AUTOSAR XML (schema 4-0-3)
standard types defined: uint8, Boolean, UInt16, UInt8, boolean
package /AUTOSAR_Platform/DataConstrs
  range DC_Boolean: raw 0..1
  range DC_UInt16: raw 0..65535
  range DC_UInt8: raw 0..255
package /DataTypes/Units
  unit NoUnit1: display-name=NoUnit, factor-si-to-unit=1, offset-si-to-unit=0
package /PATAC/Facility/DataTypes/Implementation
  compu method COMPU_Boolean: 0=FALSE, 1=TRUE
  unit NoUnit: factor-si-to-unit=1, offset-si-to-unit=0
package /PATAC/MSM/DataTypes
  impl type SeatChldLkSt: category=VALUE, base-type=BaseTypes/uint8, compu {0=ChldLkSt_NoActive, 1=ChldLkSt_Lock, 2=ChldLkSt_Unlock}
  parameter interface SeatMovCfg
    parameter data prototype Val: sw-calibration-access=READ-WRITE, type=UInt8
package /PATAC/MSM/DataTypes/Implementation
  impl type SeatSysVoltSt: category=VALUE, base-type=UInt8, compu {0=CeSMS_SysVoltNormal, 1=CeSMS_SysVoltLow, 2=CeSMS_SysVoltHigh, 3=CeSMS_SysVoltLow1, 4=CeSMS_SysVoltLow2, 5=CeSMS_SysVoltHigh1, 6=CeSMS_SysVoltHigh2}, range raw -INF..INF, type-emitter=RTE
package /PATAC/MSM/DataTypes/ImplementationDataTypes
  impl type IfVeSMSeStNumConfig: category=VALUE, base-type=UInt8, sw-calibration-access=READ-ONLY, compu {0=SeatNum4Config, 1=SeatNum6Config, 2=SeatNum7Config, 3=SeatNum4PConfig, 4=SeatNumNDLBLow, 5=SeatNumNDLBHigh}, type-emitter=RTE
package /PATAC/MSM/ModeAdjust
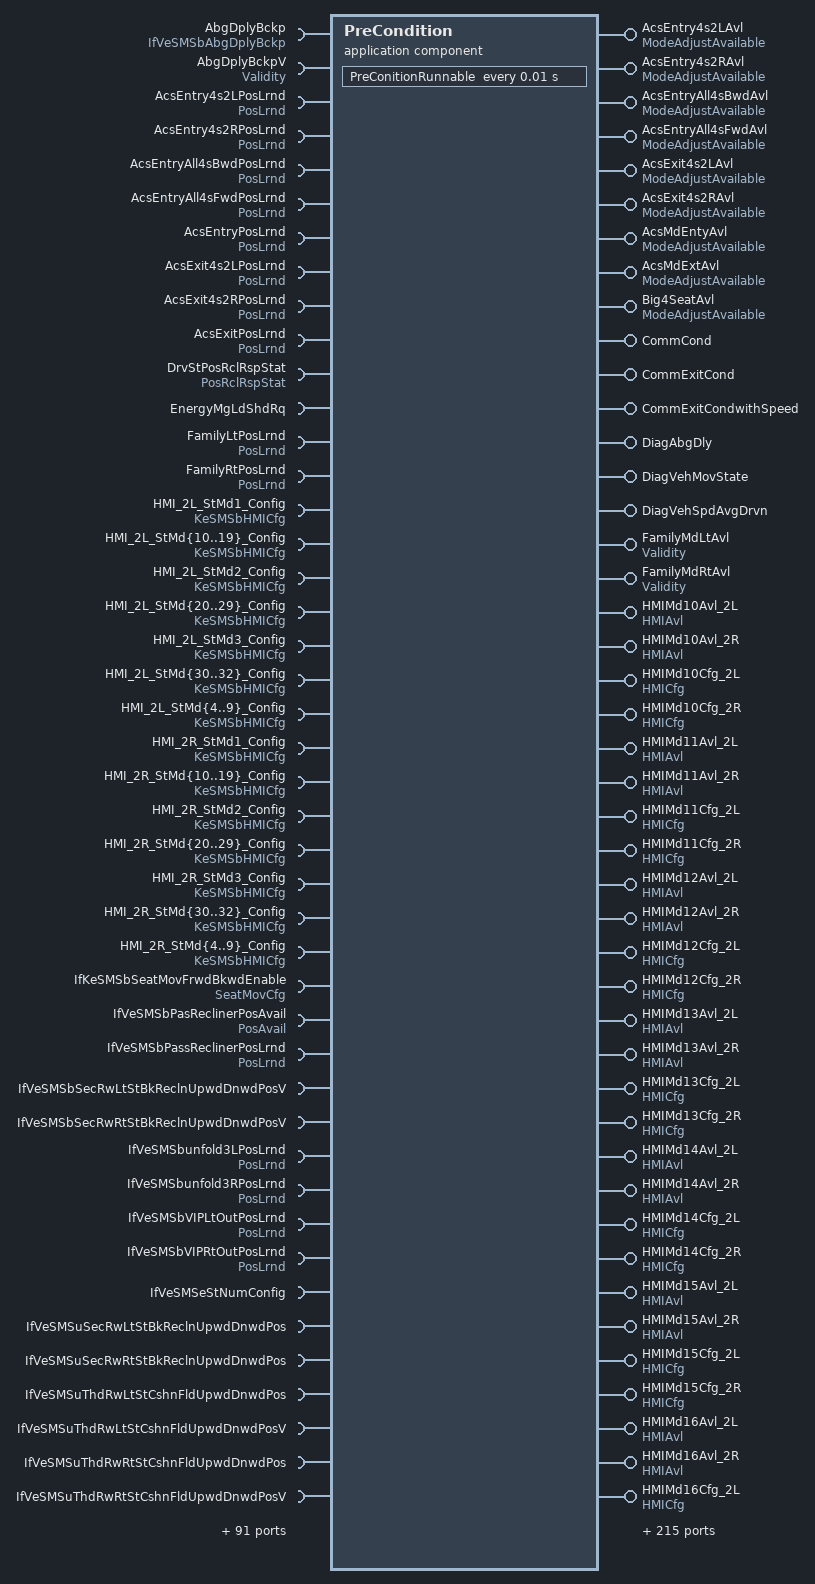
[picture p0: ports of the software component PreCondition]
  application sw component type PreCondition
    309 x provide port:
      AcsEntry4s2LAvl: nonqueued-sender-com-spec{data-element=ModeAdjustAvailable/Val, init-value=0}, provided-interface=ModeAdjustAvailable
      AcsEntry4s2RAvl: nonqueued-sender-com-spec{data-element=ModeAdjustAvailable/Val, init-value=0}, provided-interface=ModeAdjustAvailable
      AcsEntryAll4sBwdAvl: nonqueued-sender-com-spec{data-element=ModeAdjustAvailable/Val, init-value=0}, provided-interface=ModeAdjustAvailable
      AcsEntryAll4sFwdAvl: nonqueued-sender-com-spec{data-element=ModeAdjustAvailable/Val, init-value=0}, provided-interface=ModeAdjustAvailable
      AcsExit4s2LAvl: nonqueued-sender-com-spec{data-element=ModeAdjustAvailable/Val, init-value=0}, provided-interface=ModeAdjustAvailable
      AcsExit4s2RAvl: nonqueued-sender-com-spec{data-element=ModeAdjustAvailable/Val, init-value=0}, provided-interface=ModeAdjustAvailable
      AcsMdEntyAvl: nonqueued-sender-com-spec{data-element=ModeAdjustAvailable/Val, init-value=0}, provided-interface=ModeAdjustAvailable
      AcsMdExtAvl: nonqueued-sender-com-spec{data-element=ModeAdjustAvailable/Val, init-value=0}, provided-interface=ModeAdjustAvailable
      Big4SeatAvl: nonqueued-sender-com-spec{data-element=ModeAdjustAvailable/Val, init-value=0}, provided-interface=ModeAdjustAvailable
      CommCond: nonqueued-sender-com-spec=data-element=CommCond/Val, provided-interface=CommCond
      CommExitCond: nonqueued-sender-com-spec=data-element=CommExitCond/Val, provided-interface=CommExitCond
      CommExitCondwithSpeed: nonqueued-sender-com-spec=data-element=CommExitCondwithSpeed/Val, provided-interface=CommExitCondwithSpeed
      DiagAbgDly: nonqueued-sender-com-spec=data-element=DiagAbgDly/Val, provided-interface=DiagAbgDly
      DiagVehMovState: nonqueued-sender-com-spec=data-element=DiagVehMovState/Val, provided-interface=DiagVehMovState
      DiagVehSpdAvgDrvn: nonqueued-sender-com-spec=data-element=DiagVehSpdAvgDrvn/Val, provided-interface=DiagVehSpdAvgDrvn
      FamilyMdLtAvl: nonqueued-sender-com-spec{data-element=Validity/Val, init-value=0}, provided-interface=Validity
      FamilyMdRtAvl: nonqueued-sender-com-spec{data-element=Validity/Val, init-value=0}, provided-interface=Validity
      HMIMd10Avl_2L: nonqueued-sender-com-spec{data-element=HMIAvl/Val, init-value=0}, provided-interface=HMIAvl
      HMIMd10Avl_2R: nonqueued-sender-com-spec{data-element=HMIAvl/Val, init-value=0}, provided-interface=HMIAvl
      HMIMd10Cfg_2L: nonqueued-sender-com-spec{data-element=HMICfg/Val, init-value=0}, provided-interface=HMICfg
      HMIMd10Cfg_2R: nonqueued-sender-com-spec{data-element=HMICfg/Val, init-value=0}, provided-interface=HMICfg
      HMIMd11Avl_2L: nonqueued-sender-com-spec{data-element=HMIAvl/Val, init-value=0}, provided-interface=HMIAvl
      HMIMd11Avl_2R: nonqueued-sender-com-spec{data-element=HMIAvl/Val, init-value=0}, provided-interface=HMIAvl
      HMIMd11Cfg_2L: nonqueued-sender-com-spec{data-element=HMICfg/Val, init-value=0}, provided-interface=HMICfg
      HMIMd11Cfg_2R: nonqueued-sender-com-spec{data-element=HMICfg/Val, init-value=0}, provided-interface=HMICfg
      HMIMd12Avl_2L: nonqueued-sender-com-spec{data-element=HMIAvl/Val, init-value=0}, provided-interface=HMIAvl
      HMIMd12Avl_2R: nonqueued-sender-com-spec{data-element=HMIAvl/Val, init-value=0}, provided-interface=HMIAvl
      HMIMd12Cfg_2L: nonqueued-sender-com-spec{data-element=HMICfg/Val, init-value=0}, provided-interface=HMICfg
      HMIMd12Cfg_2R: nonqueued-sender-com-spec{data-element=HMICfg/Val, init-value=0}, provided-interface=HMICfg
      HMIMd13Avl_2L: nonqueued-sender-com-spec{data-element=HMIAvl/Val, init-value=0}, provided-interface=HMIAvl
      HMIMd13Avl_2R: nonqueued-sender-com-spec{data-element=HMIAvl/Val, init-value=0}, provided-interface=HMIAvl
      HMIMd13Cfg_2L: nonqueued-sender-com-spec{data-element=HMICfg/Val, init-value=0}, provided-interface=HMICfg
      HMIMd13Cfg_2R: nonqueued-sender-com-spec{data-element=HMICfg/Val, init-value=0}, provided-interface=HMICfg
      HMIMd14Avl_2L: nonqueued-sender-com-spec{data-element=HMIAvl/Val, init-value=0}, provided-interface=HMIAvl
      HMIMd14Avl_2R: nonqueued-sender-com-spec{data-element=HMIAvl/Val, init-value=0}, provided-interface=HMIAvl
      HMIMd14Cfg_2L: nonqueued-sender-com-spec{data-element=HMICfg/Val, init-value=0}, provided-interface=HMICfg
      HMIMd14Cfg_2R: nonqueued-sender-com-spec{data-element=HMICfg/Val, init-value=0}, provided-interface=HMICfg
      HMIMd15Avl_2L: nonqueued-sender-com-spec{data-element=HMIAvl/Val, init-value=0}, provided-interface=HMIAvl
      HMIMd15Avl_2R: nonqueued-sender-com-spec{data-element=HMIAvl/Val, init-value=0}, provided-interface=HMIAvl
      HMIMd15Cfg_2L: nonqueued-sender-com-spec{data-element=HMICfg/Val, init-value=0}, provided-interface=HMICfg
      HMIMd15Cfg_2R: nonqueued-sender-com-spec{data-element=HMICfg/Val, init-value=0}, provided-interface=HMICfg
      HMIMd16Avl_2L: nonqueued-sender-com-spec{data-element=HMIAvl/Val, init-value=0}, provided-interface=HMIAvl
      HMIMd16Avl_2R: nonqueued-sender-com-spec{data-element=HMIAvl/Val, init-value=0}, provided-interface=HMIAvl
      HMIMd16Cfg_2L: nonqueued-sender-com-spec{data-element=HMICfg/Val, init-value=0}, provided-interface=HMICfg
      HMIMd16Cfg_2R: nonqueued-sender-com-spec{data-element=HMICfg/Val, init-value=0}, provided-interface=HMICfg
      HMIMd17Avl_2L: nonqueued-sender-com-spec{data-element=HMIAvl/Val, init-value=0}, provided-interface=HMIAvl
      HMIMd17Avl_2R: nonqueued-sender-com-spec{data-element=HMIAvl/Val, init-value=0}, provided-interface=HMIAvl
      HMIMd17Cfg_2L: nonqueued-sender-com-spec{data-element=HMICfg/Val, init-value=0}, provided-interface=HMICfg
      HMIMd17Cfg_2R: nonqueued-sender-com-spec{data-element=HMICfg/Val, init-value=0}, provided-interface=HMICfg
      HMIMd18Avl_2L: nonqueued-sender-com-spec{data-element=HMIAvl/Val, init-value=0}, provided-interface=HMIAvl
      HMIMd18Avl_2R: nonqueued-sender-com-spec{data-element=HMIAvl/Val, init-value=0}, provided-interface=HMIAvl
      HMIMd18Cfg_2L: nonqueued-sender-com-spec{data-element=HMICfg/Val, init-value=0}, provided-interface=HMICfg
      HMIMd18Cfg_2R: nonqueued-sender-com-spec{data-element=HMICfg/Val, init-value=0}, provided-interface=HMICfg
      HMIMd19Avl_2L: nonqueued-sender-com-spec{data-element=HMIAvl/Val, init-value=0}, provided-interface=HMIAvl
      HMIMd19Avl_2R: nonqueued-sender-com-spec{data-element=HMIAvl/Val, init-value=0}, provided-interface=HMIAvl
      HMIMd19Cfg_2L: nonqueued-sender-com-spec{data-element=HMICfg/Val, init-value=0}, provided-interface=HMICfg
      HMIMd19Cfg_2R: nonqueued-sender-com-spec{data-element=HMICfg/Val, init-value=0}, provided-interface=HMICfg
      HMIMd1Avl_2L: nonqueued-sender-com-spec{data-element=HMIAvl/Val, init-value=0}, provided-interface=HMIAvl
      HMIMd1Avl_2R: nonqueued-sender-com-spec{data-element=HMIAvl/Val, init-value=0}, provided-interface=HMIAvl
      HMIMd1Cfg_2L: nonqueued-sender-com-spec{data-element=HMICfg/Val, init-value=0}, provided-interface=HMICfg
      HMIMd1Cfg_2R: nonqueued-sender-com-spec{data-element=HMICfg/Val, init-value=0}, provided-interface=HMICfg
      HMIMd20Avl_2L: nonqueued-sender-com-spec{data-element=HMIAvl/Val, init-value=0}, provided-interface=HMIAvl
      HMIMd20Avl_2R: nonqueued-sender-com-spec{data-element=HMIAvl/Val, init-value=0}, provided-interface=HMIAvl
      HMIMd20Cfg_2L: nonqueued-sender-com-spec{data-element=HMICfg/Val, init-value=0}, provided-interface=HMICfg
      HMIMd20Cfg_2R: nonqueued-sender-com-spec{data-element=HMICfg/Val, init-value=0}, provided-interface=HMICfg
      HMIMd21Avl_2L: nonqueued-sender-com-spec{data-element=HMIAvl/Val, init-value=0}, provided-interface=HMIAvl
      HMIMd21Avl_2R: nonqueued-sender-com-spec{data-element=HMIAvl/Val, init-value=0}, provided-interface=HMIAvl
      HMIMd21Cfg_2L: nonqueued-sender-com-spec{data-element=HMICfg/Val, init-value=0}, provided-interface=HMICfg
      HMIMd21Cfg_2R: nonqueued-sender-com-spec{data-element=HMICfg/Val, init-value=0}, provided-interface=HMICfg
      HMIMd22Avl_2L: nonqueued-sender-com-spec{data-element=HMIAvl/Val, init-value=0}, provided-interface=HMIAvl
      HMIMd22Avl_2R: nonqueued-sender-com-spec{data-element=HMIAvl/Val, init-value=0}, provided-interface=HMIAvl
      HMIMd22Cfg_2L: nonqueued-sender-com-spec{data-element=HMICfg/Val, init-value=0}, provided-interface=HMICfg
      HMIMd22Cfg_2R: nonqueued-sender-com-spec{data-element=HMICfg/Val, init-value=0}, provided-interface=HMICfg
      HMIMd23Avl_2L: nonqueued-sender-com-spec{data-element=HMIAvl/Val, init-value=0}, provided-interface=HMIAvl
      HMIMd23Avl_2R: nonqueued-sender-com-spec{data-element=HMIAvl/Val, init-value=0}, provided-interface=HMIAvl
      HMIMd23Cfg_2L: nonqueued-sender-com-spec{data-element=HMICfg/Val, init-value=0}, provided-interface=HMICfg
      HMIMd23Cfg_2R: nonqueued-sender-com-spec{data-element=HMICfg/Val, init-value=0}, provided-interface=HMICfg
      HMIMd24Avl_2L: nonqueued-sender-com-spec{data-element=HMIAvl/Val, init-value=0}, provided-interface=HMIAvl
      HMIMd24Avl_2R: nonqueued-sender-com-spec{data-element=HMIAvl/Val, init-value=0}, provided-interface=HMIAvl
      HMIMd24Cfg_2L: nonqueued-sender-com-spec{data-element=HMICfg/Val, init-value=0}, provided-interface=HMICfg
      HMIMd24Cfg_2R: nonqueued-sender-com-spec{data-element=HMICfg/Val, init-value=0}, provided-interface=HMICfg
      HMIMd25Avl_2L: nonqueued-sender-com-spec{data-element=HMIAvl/Val, init-value=0}, provided-interface=HMIAvl
      HMIMd25Avl_2R: nonqueued-sender-com-spec{data-element=HMIAvl/Val, init-value=0}, provided-interface=HMIAvl
      HMIMd25Cfg_2L: nonqueued-sender-com-spec{data-element=HMICfg/Val, init-value=0}, provided-interface=HMICfg
      HMIMd25Cfg_2R: nonqueued-sender-com-spec{data-element=HMICfg/Val, init-value=0}, provided-interface=HMICfg
      HMIMd26Avl_2L: nonqueued-sender-com-spec{data-element=HMIAvl/Val, init-value=0}, provided-interface=HMIAvl
      HMIMd26Avl_2R: nonqueued-sender-com-spec{data-element=HMIAvl/Val, init-value=0}, provided-interface=HMIAvl
      HMIMd26Cfg_2L: nonqueued-sender-com-spec{data-element=HMICfg/Val, init-value=0}, provided-interface=HMICfg
      HMIMd26Cfg_2R: nonqueued-sender-com-spec{data-element=HMICfg/Val, init-value=0}, provided-interface=HMICfg
      HMIMd27Avl_2L: nonqueued-sender-com-spec{data-element=HMIAvl/Val, init-value=0}, provided-interface=HMIAvl
      HMIMd27Avl_2R: nonqueued-sender-com-spec{data-element=HMIAvl/Val, init-value=0}, provided-interface=HMIAvl
      HMIMd27Cfg_2L: nonqueued-sender-com-spec{data-element=HMICfg/Val, init-value=0}, provided-interface=HMICfg
      HMIMd27Cfg_2R: nonqueued-sender-com-spec{data-element=HMICfg/Val, init-value=0}, provided-interface=HMICfg
      HMIMd28Avl_2L: nonqueued-sender-com-spec{data-element=HMIAvl/Val, init-value=0}, provided-interface=HMIAvl
      HMIMd28Avl_2R: nonqueued-sender-com-spec{data-element=HMIAvl/Val, init-value=0}, provided-interface=HMIAvl
      HMIMd28Cfg_2L: nonqueued-sender-com-spec{data-element=HMICfg/Val, init-value=0}, provided-interface=HMICfg
      HMIMd28Cfg_2R: nonqueued-sender-com-spec{data-element=HMICfg/Val, init-value=0}, provided-interface=HMICfg
      HMIMd29Avl_2L: nonqueued-sender-com-spec{data-element=HMIAvl/Val, init-value=0}, provided-interface=HMIAvl
      HMIMd29Avl_2R: nonqueued-sender-com-spec{data-element=HMIAvl/Val, init-value=0}, provided-interface=HMIAvl
      HMIMd29Cfg_2L: nonqueued-sender-com-spec{data-element=HMICfg/Val, init-value=0}, provided-interface=HMICfg
      HMIMd29Cfg_2R: nonqueued-sender-com-spec{data-element=HMICfg/Val, init-value=0}, provided-interface=HMICfg
      HMIMd2Avl_2L: nonqueued-sender-com-spec{data-element=HMIAvl/Val, init-value=0}, provided-interface=HMIAvl
      HMIMd2Avl_2R: nonqueued-sender-com-spec{data-element=HMIAvl/Val, init-value=0}, provided-interface=HMIAvl
      HMIMd2Cfg_2L: nonqueued-sender-com-spec{data-element=HMICfg/Val, init-value=0}, provided-interface=HMICfg
      HMIMd2Cfg_2R: nonqueued-sender-com-spec{data-element=HMICfg/Val, init-value=0}, provided-interface=HMICfg
      HMIMd30Avl_2L: nonqueued-sender-com-spec{data-element=HMIAvl/Val, init-value=0}, provided-interface=HMIAvl
      HMIMd30Avl_2R: nonqueued-sender-com-spec{data-element=HMIAvl/Val, init-value=0}, provided-interface=HMIAvl
      HMIMd30Cfg_2L: nonqueued-sender-com-spec{data-element=HMICfg/Val, init-value=0}, provided-interface=HMICfg
      HMIMd30Cfg_2R: nonqueued-sender-com-spec{data-element=HMICfg/Val, init-value=0}, provided-interface=HMICfg
      HMIMd31Avl_2L: nonqueued-sender-com-spec{data-element=HMIAvl/Val, init-value=0}, provided-interface=HMIAvl
      HMIMd31Avl_2R: nonqueued-sender-com-spec{data-element=HMIAvl/Val, init-value=0}, provided-interface=HMIAvl
      HMIMd31Cfg_2L: nonqueued-sender-com-spec{data-element=HMICfg/Val, init-value=0}, provided-interface=HMICfg
      HMIMd31Cfg_2R: nonqueued-sender-com-spec{data-element=HMICfg/Val, init-value=0}, provided-interface=HMICfg
      HMIMd32Avl_2L: nonqueued-sender-com-spec{data-element=HMIAvl/Val, init-value=0}, provided-interface=HMIAvl
      HMIMd32Avl_2R: nonqueued-sender-com-spec{data-element=HMIAvl/Val, init-value=0}, provided-interface=HMIAvl
      HMIMd32Cfg_2L: nonqueued-sender-com-spec{data-element=HMICfg/Val, init-value=0}, provided-interface=HMICfg
      HMIMd32Cfg_2R: nonqueued-sender-com-spec{data-element=HMICfg/Val, init-value=0}, provided-interface=HMICfg
      HMIMd3Avl_2L: nonqueued-sender-com-spec{data-element=HMIAvl/Val, init-value=0}, provided-interface=HMIAvl
      HMIMd3Avl_2R: nonqueued-sender-com-spec{data-element=HMIAvl/Val, init-value=0}, provided-interface=HMIAvl
      HMIMd3Cfg_2L: nonqueued-sender-com-spec{data-element=HMICfg/Val, init-value=0}, provided-interface=HMICfg
      HMIMd3Cfg_2R: nonqueued-sender-com-spec{data-element=HMICfg/Val, init-value=0}, provided-interface=HMICfg
      HMIMd4Avl_2L: nonqueued-sender-com-spec{data-element=HMIAvl/Val, init-value=0}, provided-interface=HMIAvl
      HMIMd4Avl_2R: nonqueued-sender-com-spec{data-element=HMIAvl/Val, init-value=0}, provided-interface=HMIAvl
      HMIMd4Cfg_2L: nonqueued-sender-com-spec{data-element=HMICfg/Val, init-value=0}, provided-interface=HMICfg
      HMIMd4Cfg_2R: nonqueued-sender-com-spec{data-element=HMICfg/Val, init-value=0}, provided-interface=HMICfg
      HMIMd5Avl_2L: nonqueued-sender-com-spec{data-element=HMIAvl/Val, init-value=0}, provided-interface=HMIAvl
      HMIMd5Avl_2R: nonqueued-sender-com-spec{data-element=HMIAvl/Val, init-value=0}, provided-interface=HMIAvl
      HMIMd5Cfg_2L: nonqueued-sender-com-spec{data-element=HMICfg/Val, init-value=0}, provided-interface=HMICfg
      HMIMd5Cfg_2R: nonqueued-sender-com-spec{data-element=HMICfg/Val, init-value=0}, provided-interface=HMICfg
      HMIMd6Avl_2L: nonqueued-sender-com-spec{data-element=HMIAvl/Val, init-value=0}, provided-interface=HMIAvl
      HMIMd6Avl_2R: nonqueued-sender-com-spec{data-element=HMIAvl/Val, init-value=0}, provided-interface=HMIAvl
      HMIMd6Cfg_2L: nonqueued-sender-com-spec{data-element=HMICfg/Val, init-value=0}, provided-interface=HMICfg
      HMIMd6Cfg_2R: nonqueued-sender-com-spec{data-element=HMICfg/Val, init-value=0}, provided-interface=HMICfg
      HMIMd7Avl_2L: nonqueued-sender-com-spec{data-element=HMIAvl/Val, init-value=0}, provided-interface=HMIAvl
      HMIMd7Avl_2R: nonqueued-sender-com-spec{data-element=HMIAvl/Val, init-value=0}, provided-interface=HMIAvl
      HMIMd7Cfg_2L: nonqueued-sender-com-spec{data-element=HMICfg/Val, init-value=0}, provided-interface=HMICfg
      HMIMd7Cfg_2R: nonqueued-sender-com-spec{data-element=HMICfg/Val, init-value=0}, provided-interface=HMICfg
      HMIMd8Avl_2L: nonqueued-sender-com-spec{data-element=HMIAvl/Val, init-value=0}, provided-interface=HMIAvl
      HMIMd8Avl_2R: nonqueued-sender-com-spec{data-element=HMIAvl/Val, init-value=0}, provided-interface=HMIAvl
      HMIMd8Cfg_2L: nonqueued-sender-com-spec{data-element=HMICfg/Val, init-value=0}, provided-interface=HMICfg
      HMIMd8Cfg_2R: nonqueued-sender-com-spec{data-element=HMICfg/Val, init-value=0}, provided-interface=HMICfg
      HMIMd9Avl_2L: nonqueued-sender-com-spec{data-element=HMIAvl/Val, init-value=0}, provided-interface=HMIAvl
      HMIMd9Avl_2R: nonqueued-sender-com-spec{data-element=HMIAvl/Val, init-value=0}, provided-interface=HMIAvl
      HMIMd9Cfg_2L: nonqueued-sender-com-spec{data-element=HMICfg/Val, init-value=0}, provided-interface=HMICfg
      HMIMd9Cfg_2R: nonqueued-sender-com-spec{data-element=HMICfg/Val, init-value=0}, provided-interface=HMICfg
      IntimacyLMdAvl: nonqueued-sender-com-spec{data-element=Validity/Val, init-value=0}, provided-interface=Validity
      IntimacyRMdAvl: nonqueued-sender-com-spec{data-element=ModeAdjustAvailable/Val, init-value=0}, provided-interface=ModeAdjustAvailable
      LgrstCloseLtMdAvl: nonqueued-sender-com-spec{data-element=ModeAdjustAvailable/Val, init-value=0}, provided-interface=ModeAdjustAvailable
      LgrstCloseRtMdAvl: nonqueued-sender-com-spec{data-element=ModeAdjustAvailable/Val, init-value=0}, provided-interface=ModeAdjustAvailable
      LgrstOpenLtMdAvl: nonqueued-sender-com-spec{data-element=ModeAdjustAvailable/Val, init-value=0}, provided-interface=ModeAdjustAvailable
      LgrstOpenRtMdAvl: nonqueued-sender-com-spec{data-element=ModeAdjustAvailable/Val, init-value=0}, provided-interface=ModeAdjustAvailable
      LugMdLtAvl: nonqueued-sender-com-spec{data-element=ModeAdjustAvailable/Val, init-value=0}, provided-interface=ModeAdjustAvailable
      LugMdRtAvl: nonqueued-sender-com-spec{data-element=ModeAdjustAvailable/Val, init-value=0}, provided-interface=ModeAdjustAvailable
      LyingMdLtAvl: nonqueued-sender-com-spec{data-element=Validity/Val, init-value=0}, provided-interface=Validity
      LyingMdRtAvl: nonqueued-sender-com-spec{data-element=Validity/Val, init-value=0}, provided-interface=Validity
      M61WholeVehMemAvl: nonqueued-sender-com-spec{data-element=ModeAdjustAvailable/Val, init-value=0}, provided-interface=ModeAdjustAvailable
      M62WholeVehMemAvl: nonqueued-sender-com-spec{data-element=ModeAdjustAvailable/Val, init-value=0}, provided-interface=ModeAdjustAvailable
      PasReclinerAvl: nonqueued-sender-com-spec{data-element=ModeAdjustAvailable/Val, init-value=0}, provided-interface=ModeAdjustAvailable
      PasReclinerExitAvl: nonqueued-sender-com-spec{data-element=ModeAdjustAvailable/Val, init-value=0}, provided-interface=ModeAdjustAvailable
      PwrMdChked: nonqueued-sender-com-spec{data-element=PowerMode/Val, init-value=0}, provided-interface=PowerMode
      RcvyMdLtAvl: nonqueued-sender-com-spec{data-element=ModeAdjustAvailable/Val, init-value=0}, provided-interface=ModeAdjustAvailable
      RcvyMdRtAvl: nonqueued-sender-com-spec{data-element=ModeAdjustAvailable/Val, init-value=0}, provided-interface=ModeAdjustAvailable
      StPassCmprtMdCtrl_Md1_VCUAvl: nonqueued-sender-com-spec{data-element=StPassCmprtMdCtrl_VCUAvl/Val, init-value=0}, provided-interface=StPassCmprtMdCtrl_VCUAvl
      StPassCmprtMdCtrl_Md1_VCUCfg: nonqueued-sender-com-spec{data-element=StPassCmprtMd_VCUCfg/Val, init-value=0}, provided-interface=StPassCmprtMd_VCUCfg
      StPassCmprtMdCtrl_Md10_VCUAvl: nonqueued-sender-com-spec{data-element=StPassCmprtMdCtrl_VCUAvl/Val, init-value=0}, provided-interface=StPassCmprtMdCtrl_VCUAvl
      StPassCmprtMdCtrl_Md10_VCUCfg: nonqueued-sender-com-spec{data-element=StPassCmprtMd_VCUCfg/Val, init-value=0}, provided-interface=StPassCmprtMd_VCUCfg
      StPassCmprtMdCtrl_Md11_VCUAvl: nonqueued-sender-com-spec{data-element=StPassCmprtMdCtrl_VCUAvl/Val, init-value=0}, provided-interface=StPassCmprtMdCtrl_VCUAvl
      StPassCmprtMdCtrl_Md11_VCUCfg: nonqueued-sender-com-spec{data-element=StPassCmprtMd_VCUCfg/Val, init-value=0}, provided-interface=StPassCmprtMd_VCUCfg
      StPassCmprtMdCtrl_Md12_VCUAvl: nonqueued-sender-com-spec{data-element=StPassCmprtMdCtrl_VCUAvl/Val, init-value=0}, provided-interface=StPassCmprtMdCtrl_VCUAvl
      StPassCmprtMdCtrl_Md12_VCUCfg: nonqueued-sender-com-spec{data-element=StPassCmprtMd_VCUCfg/Val, init-value=0}, provided-interface=StPassCmprtMd_VCUCfg
      StPassCmprtMdCtrl_Md13_VCUAvl: nonqueued-sender-com-spec{data-element=StPassCmprtMdCtrl_VCUAvl/Val, init-value=0}, provided-interface=StPassCmprtMdCtrl_VCUAvl
      StPassCmprtMdCtrl_Md13_VCUCfg: nonqueued-sender-com-spec{data-element=StPassCmprtMd_VCUCfg/Val, init-value=0}, provided-interface=StPassCmprtMd_VCUCfg
      StPassCmprtMdCtrl_Md14_VCUAvl: nonqueued-sender-com-spec{data-element=StPassCmprtMdCtrl_VCUAvl/Val, init-value=0}, provided-interface=StPassCmprtMdCtrl_VCUAvl
      StPassCmprtMdCtrl_Md14_VCUCfg: nonqueued-sender-com-spec{data-element=StPassCmprtMd_VCUCfg/Val, init-value=0}, provided-interface=StPassCmprtMd_VCUCfg
      StPassCmprtMdCtrl_Md15_VCUAvl: nonqueued-sender-com-spec{data-element=StPassCmprtMdCtrl_VCUAvl/Val, init-value=0}, provided-interface=StPassCmprtMdCtrl_VCUAvl
      StPassCmprtMdCtrl_Md15_VCUCfg: nonqueued-sender-com-spec{data-element=StPassCmprtMd_VCUCfg/Val, init-value=0}, provided-interface=StPassCmprtMd_VCUCfg
      StPassCmprtMdCtrl_Md16_VCUAvl: nonqueued-sender-com-spec{data-element=StPassCmprtMdCtrl_VCUAvl/Val, init-value=0}, provided-interface=StPassCmprtMdCtrl_VCUAvl
      StPassCmprtMdCtrl_Md16_VCUCfg: nonqueued-sender-com-spec{data-element=StPassCmprtMd_VCUCfg/Val, init-value=0}, provided-interface=StPassCmprtMd_VCUCfg
      StPassCmprtMdCtrl_Md17_VCUAvl: nonqueued-sender-com-spec{data-element=StPassCmprtMdCtrl_VCUAvl/Val, init-value=0}, provided-interface=StPassCmprtMdCtrl_VCUAvl
      StPassCmprtMdCtrl_Md17_VCUCfg: nonqueued-sender-com-spec{data-element=StPassCmprtMd_VCUCfg/Val, init-value=0}, provided-interface=StPassCmprtMd_VCUCfg
      StPassCmprtMdCtrl_Md18_VCUAvl: nonqueued-sender-com-spec{data-element=StPassCmprtMdCtrl_VCUAvl/Val, init-value=0}, provided-interface=StPassCmprtMdCtrl_VCUAvl
      StPassCmprtMdCtrl_Md18_VCUCfg: nonqueued-sender-com-spec{data-element=StPassCmprtMd_VCUCfg/Val, init-value=0}, provided-interface=StPassCmprtMd_VCUCfg
      StPassCmprtMdCtrl_Md19_VCUAvl: nonqueued-sender-com-spec{data-element=StPassCmprtMdCtrl_VCUAvl/Val, init-value=0}, provided-interface=StPassCmprtMdCtrl_VCUAvl
      StPassCmprtMdCtrl_Md19_VCUCfg: nonqueued-sender-com-spec{data-element=StPassCmprtMd_VCUCfg/Val, init-value=0}, provided-interface=StPassCmprtMd_VCUCfg
      StPassCmprtMdCtrl_Md2_VCUAvl: nonqueued-sender-com-spec{data-element=StPassCmprtMdCtrl_VCUAvl/Val, init-value=0}, provided-interface=StPassCmprtMdCtrl_VCUAvl
      StPassCmprtMdCtrl_Md2_VCUCfg: nonqueued-sender-com-spec{data-element=StPassCmprtMd_VCUCfg/Val, init-value=0}, provided-interface=StPassCmprtMd_VCUCfg
      StPassCmprtMdCtrl_Md20_VCUAvl: nonqueued-sender-com-spec{data-element=StPassCmprtMdCtrl_VCUAvl/Val, init-value=0}, provided-interface=StPassCmprtMdCtrl_VCUAvl
      StPassCmprtMdCtrl_Md20_VCUCfg: nonqueued-sender-com-spec{data-element=StPassCmprtMd_VCUCfg/Val, init-value=0}, provided-interface=StPassCmprtMd_VCUCfg
      StPassCmprtMdCtrl_Md21_VCUAvl: nonqueued-sender-com-spec{data-element=StPassCmprtMdCtrl_VCUAvl/Val, init-value=0}, provided-interface=StPassCmprtMdCtrl_VCUAvl
      StPassCmprtMdCtrl_Md21_VCUCfg: nonqueued-sender-com-spec{data-element=StPassCmprtMd_VCUCfg/Val, init-value=0}, provided-interface=StPassCmprtMd_VCUCfg
      StPassCmprtMdCtrl_Md22_VCUAvl: nonqueued-sender-com-spec{data-element=StPassCmprtMdCtrl_VCUAvl/Val, init-value=0}, provided-interface=StPassCmprtMdCtrl_VCUAvl
      StPassCmprtMdCtrl_Md22_VCUCfg: nonqueued-sender-com-spec{data-element=StPassCmprtMd_VCUCfg/Val, init-value=0}, provided-interface=StPassCmprtMd_VCUCfg
      StPassCmprtMdCtrl_Md23_VCUAvl: nonqueued-sender-com-spec{data-element=StPassCmprtMdCtrl_VCUAvl/Val, init-value=0}, provided-interface=StPassCmprtMdCtrl_VCUAvl
      StPassCmprtMdCtrl_Md23_VCUCfg: nonqueued-sender-com-spec{data-element=StPassCmprtMd_VCUCfg/Val, init-value=0}, provided-interface=StPassCmprtMd_VCUCfg
      StPassCmprtMdCtrl_Md24_VCUAvl: nonqueued-sender-com-spec{data-element=StPassCmprtMdCtrl_VCUAvl/Val, init-value=0}, provided-interface=StPassCmprtMdCtrl_VCUAvl
      StPassCmprtMdCtrl_Md24_VCUCfg: nonqueued-sender-com-spec{data-element=StPassCmprtMd_VCUCfg/Val, init-value=0}, provided-interface=StPassCmprtMd_VCUCfg
      StPassCmprtMdCtrl_Md25_VCUAvl: nonqueued-sender-com-spec{data-element=StPassCmprtMdCtrl_VCUAvl/Val, init-value=0}, provided-interface=StPassCmprtMdCtrl_VCUAvl
      StPassCmprtMdCtrl_Md25_VCUCfg: nonqueued-sender-com-spec{data-element=StPassCmprtMd_VCUCfg/Val, init-value=0}, provided-interface=StPassCmprtMd_VCUCfg
      StPassCmprtMdCtrl_Md26_VCUAvl: nonqueued-sender-com-spec{data-element=StPassCmprtMdCtrl_VCUAvl/Val, init-value=0}, provided-interface=StPassCmprtMdCtrl_VCUAvl
      StPassCmprtMdCtrl_Md26_VCUCfg: nonqueued-sender-com-spec{data-element=StPassCmprtMd_VCUCfg/Val, init-value=0}, provided-interface=StPassCmprtMd_VCUCfg
      StPassCmprtMdCtrl_Md27_VCUAvl: nonqueued-sender-com-spec{data-element=StPassCmprtMdCtrl_VCUAvl/Val, init-value=0}, provided-interface=StPassCmprtMdCtrl_VCUAvl
      StPassCmprtMdCtrl_Md27_VCUCfg: nonqueued-sender-com-spec{data-element=StPassCmprtMd_VCUCfg/Val, init-value=0}, provided-interface=StPassCmprtMd_VCUCfg
      StPassCmprtMdCtrl_Md28_VCUAvl: nonqueued-sender-com-spec{data-element=StPassCmprtMdCtrl_VCUAvl/Val, init-value=0}, provided-interface=StPassCmprtMdCtrl_VCUAvl
      StPassCmprtMdCtrl_Md28_VCUCfg: nonqueued-sender-com-spec{data-element=StPassCmprtMd_VCUCfg/Val, init-value=0}, provided-interface=StPassCmprtMd_VCUCfg
      StPassCmprtMdCtrl_Md29_VCUAvl: nonqueued-sender-com-spec{data-element=StPassCmprtMdCtrl_VCUAvl/Val, init-value=0}, provided-interface=StPassCmprtMdCtrl_VCUAvl
      StPassCmprtMdCtrl_Md29_VCUCfg: nonqueued-sender-com-spec{data-element=StPassCmprtMd_VCUCfg/Val, init-value=0}, provided-interface=StPassCmprtMd_VCUCfg
      StPassCmprtMdCtrl_Md3_VCUAvl: nonqueued-sender-com-spec{data-element=StPassCmprtMdCtrl_VCUAvl/Val, init-value=0}, provided-interface=StPassCmprtMdCtrl_VCUAvl
      StPassCmprtMdCtrl_Md3_VCUCfg: nonqueued-sender-com-spec{data-element=StPassCmprtMd_VCUCfg/Val, init-value=0}, provided-interface=StPassCmprtMd_VCUCfg
      StPassCmprtMdCtrl_Md30_VCUAvl: nonqueued-sender-com-spec{data-element=StPassCmprtMdCtrl_VCUAvl/Val, init-value=0}, provided-interface=StPassCmprtMdCtrl_VCUAvl
      StPassCmprtMdCtrl_Md30_VCUCfg: nonqueued-sender-com-spec{data-element=StPassCmprtMd_VCUCfg/Val, init-value=0}, provided-interface=StPassCmprtMd_VCUCfg
      StPassCmprtMdCtrl_Md31_VCUAvl: nonqueued-sender-com-spec{data-element=StPassCmprtMdCtrl_VCUAvl/Val, init-value=0}, provided-interface=StPassCmprtMdCtrl_VCUAvl
      StPassCmprtMdCtrl_Md31_VCUCfg: nonqueued-sender-com-spec{data-element=StPassCmprtMd_VCUCfg/Val, init-value=0}, provided-interface=StPassCmprtMd_VCUCfg
      StPassCmprtMdCtrl_Md32_VCUAvl: nonqueued-sender-com-spec{data-element=StPassCmprtMdCtrl_VCUAvl/Val, init-value=0}, provided-interface=StPassCmprtMdCtrl_VCUAvl
      StPassCmprtMdCtrl_Md32_VCUCfg: nonqueued-sender-com-spec{data-element=StPassCmprtMd_VCUCfg/Val, init-value=0}, provided-interface=StPassCmprtMd_VCUCfg
      StPassCmprtMdCtrl_Md4_VCUAvl: nonqueued-sender-com-spec{data-element=StPassCmprtMdCtrl_VCUAvl/Val, init-value=0}, provided-interface=StPassCmprtMdCtrl_VCUAvl
      StPassCmprtMdCtrl_Md4_VCUCfg: nonqueued-sender-com-spec{data-element=StPassCmprtMd_VCUCfg/Val, init-value=0}, provided-interface=StPassCmprtMd_VCUCfg
      StPassCmprtMdCtrl_Md5_VCUAvl: nonqueued-sender-com-spec{data-element=StPassCmprtMdCtrl_VCUAvl/Val, init-value=0}, provided-interface=StPassCmprtMdCtrl_VCUAvl
      StPassCmprtMdCtrl_Md5_VCUCfg: nonqueued-sender-com-spec{data-element=StPassCmprtMd_VCUCfg/Val, init-value=0}, provided-interface=StPassCmprtMd_VCUCfg
      StPassCmprtMdCtrl_Md53_VCUAvl: nonqueued-sender-com-spec{data-element=StPassCmprtMdCtrl_VCUAvl/Val, init-value=0}, provided-interface=StPassCmprtMdCtrl_VCUAvl
      StPassCmprtMdCtrl_Md53_VCUCfg: nonqueued-sender-com-spec{data-element=StPassCmprtMd_VCUCfg/Val, init-value=0}, provided-interface=StPassCmprtMd_VCUCfg
      StPassCmprtMdCtrl_Md56_VCUAvl: nonqueued-sender-com-spec{data-element=StPassCmprtMdCtrl_VCUAvl/Val, init-value=0}, provided-interface=StPassCmprtMdCtrl_VCUAvl
      StPassCmprtMdCtrl_Md56_VCUCfg: nonqueued-sender-com-spec{data-element=StPassCmprtMd_VCUCfg/Val, init-value=0}, provided-interface=StPassCmprtMd_VCUCfg
      StPassCmprtMdCtrl_Md57_VCUAvl: nonqueued-sender-com-spec{data-element=StPassCmprtMdCtrl_VCUAvl/Val, init-value=0}, provided-interface=StPassCmprtMdCtrl_VCUAvl
      StPassCmprtMdCtrl_Md57_VCUCfg: nonqueued-sender-com-spec{data-element=StPassCmprtMd_VCUCfg/Val, init-value=0}, provided-interface=StPassCmprtMd_VCUCfg
      StPassCmprtMdCtrl_Md58_VCUAvl: nonqueued-sender-com-spec{data-element=StPassCmprtMdCtrl_VCUAvl/Val, init-value=0}, provided-interface=StPassCmprtMdCtrl_VCUAvl
      StPassCmprtMdCtrl_Md58_VCUCfg: nonqueued-sender-com-spec{data-element=StPassCmprtMd_VCUCfg/Val, init-value=0}, provided-interface=StPassCmprtMd_VCUCfg
      StPassCmprtMdCtrl_Md6_VCUAvl: nonqueued-sender-com-spec{data-element=StPassCmprtMdCtrl_VCUAvl/Val, init-value=0}, provided-interface=StPassCmprtMdCtrl_VCUAvl
      StPassCmprtMdCtrl_Md6_VCUCfg: nonqueued-sender-com-spec{data-element=StPassCmprtMd_VCUCfg/Val, init-value=0}, provided-interface=StPassCmprtMd_VCUCfg
      StPassCmprtMdCtrl_Md61_VCUAvl: nonqueued-sender-com-spec{data-element=StPassCmprtMdCtrl_VCUAvl/Val, init-value=0}, provided-interface=StPassCmprtMdCtrl_VCUAvl
      StPassCmprtMdCtrl_Md61_VCUCfg: nonqueued-sender-com-spec{data-element=StPassCmprtMd_VCUCfg/Val, init-value=0}, provided-interface=StPassCmprtMd_VCUCfg
      StPassCmprtMdCtrl_Md62_VCUAvl: nonqueued-sender-com-spec{data-element=StPassCmprtMdCtrl_VCUAvl/Val, init-value=0}, provided-interface=StPassCmprtMdCtrl_VCUAvl
      StPassCmprtMdCtrl_Md62_VCUCfg: nonqueued-sender-com-spec{data-element=StPassCmprtMd_VCUCfg/Val, init-value=0}, provided-interface=StPassCmprtMd_VCUCfg
      StPassCmprtMdCtrl_Md7_VCUAvl: nonqueued-sender-com-spec{data-element=StPassCmprtMdCtrl_VCUAvl/Val, init-value=0}, provided-interface=StPassCmprtMdCtrl_VCUAvl
      StPassCmprtMdCtrl_Md7_VCUCfg: nonqueued-sender-com-spec{data-element=StPassCmprtMd_VCUCfg/Val, init-value=0}, provided-interface=StPassCmprtMd_VCUCfg
      StPassCmprtMdCtrl_Md8_VCUAvl: nonqueued-sender-com-spec{data-element=StPassCmprtMdCtrl_VCUAvl/Val, init-value=0}, provided-interface=StPassCmprtMdCtrl_VCUAvl
      StPassCmprtMdCtrl_Md8_VCUCfg: nonqueued-sender-com-spec{data-element=StPassCmprtMd_VCUCfg/Val, init-value=0}, provided-interface=StPassCmprtMd_VCUCfg
      StPassCmprtMdCtrl_Md9_VCUAvl: nonqueued-sender-com-spec{data-element=StPassCmprtMdCtrl_VCUAvl/Val, init-value=0}, provided-interface=StPassCmprtMdCtrl_VCUAvl
      StPassCmprtMdCtrl_Md9_VCUCfg: nonqueued-sender-com-spec{data-element=StPassCmprtMd_VCUCfg/Val, init-value=0}, provided-interface=StPassCmprtMd_VCUCfg
      StPassCmprtMdRfCtrlSwCstStAvl: nonqueued-sender-com-spec{data-element=StPassCmprtMdRfCtrlSwCstStAvl/Val, init-value=0}, provided-interface=StPassCmprtMdRfCtrlSwCstStAvl
      StSrvAvl_Md1: nonqueued-sender-com-spec{data-element=StSrvAvl/Val, init-value=0}, provided-interface=StSrvAvl
      StSrvAvl_Md{10..19}: nonqueued-sender-com-spec{data-element=StSrvAvl/Val, init-value=0}, provided-interface=StSrvAvl
      StSrvAvl_Md2: nonqueued-sender-com-spec{data-element=StSrvAvl/Val, init-value=0}, provided-interface=StSrvAvl
      StSrvAvl_Md{20..29}: nonqueued-sender-com-spec{data-element=StSrvAvl/Val, init-value=0}, provided-interface=StSrvAvl
      StSrvAvl_Md3: nonqueued-sender-com-spec{data-element=StSrvAvl/Val, init-value=0}, provided-interface=StSrvAvl
      StSrvAvl_Md{30..32}: nonqueued-sender-com-spec{data-element=StSrvAvl/Val, init-value=0}, provided-interface=StSrvAvl
      StSrvAvl_Md{4..9}: nonqueued-sender-com-spec{data-element=StSrvAvl/Val, init-value=0}, provided-interface=StSrvAvl
      StSrvCfg_Md1: nonqueued-sender-com-spec{data-element=StSrvCfg/Val, init-value=0}, provided-interface=StSrvCfg
      StSrvCfg_Md{10..19}: nonqueued-sender-com-spec{data-element=StSrvCfg/Val, init-value=0}, provided-interface=StSrvCfg
      StSrvCfg_Md2: nonqueued-sender-com-spec{data-element=StSrvCfg/Val, init-value=0}, provided-interface=StSrvCfg
      StSrvCfg_Md{20..29}: nonqueued-sender-com-spec{data-element=StSrvCfg/Val, init-value=0}, provided-interface=StSrvCfg
      StSrvCfg_Md3: nonqueued-sender-com-spec{data-element=StSrvCfg/Val, init-value=0}, provided-interface=StSrvCfg
      StSrvCfg_Md{30..32}: nonqueued-sender-com-spec{data-element=StSrvCfg/Val, init-value=0}, provided-interface=StSrvCfg
      StSrvCfg_Md{4..9}: nonqueued-sender-com-spec{data-element=StSrvCfg/Val, init-value=0}, provided-interface=StSrvCfg
      unfold3LAvl: nonqueued-sender-com-spec{data-element=ModeAdjustAvailable/Val, init-value=0}, provided-interface=ModeAdjustAvailable
      unfold3RAvl: nonqueued-sender-com-spec{data-element=ModeAdjustAvailable/Val, init-value=0}, provided-interface=ModeAdjustAvailable
      VipLtOutMdAvl: nonqueued-sender-com-spec{data-element=ModeAdjustAvailable/Val, init-value=0}, provided-interface=ModeAdjustAvailable
      VipMdLtAvl: nonqueued-sender-com-spec{data-element=ModeAdjustAvailable/Val, init-value=0}, provided-interface=ModeAdjustAvailable
      VipMdRtAvl: nonqueued-sender-com-spec{data-element=ModeAdjustAvailable/Val, init-value=0}, provided-interface=ModeAdjustAvailable
      VipRtOutMdAvl: nonqueued-sender-com-spec{data-element=ModeAdjustAvailable/Val, init-value=0}, provided-interface=ModeAdjustAvailable
    234 x require port:
      AbgDplyBckp: nonqueued-receiver-com-spec{data-element=IfVeSMSbAbgDplyBckp/Val, filter=data-filter-type=ALWAYS, init-value=1}, required-interface=IfVeSMSbAbgDplyBckp
      AbgDplyBckpV: nonqueued-receiver-com-spec{data-element=Validity/Val, filter=data-filter-type=ALWAYS, init-value=0}, required-interface=Validity
      AcsEntry4s2LPosLrnd: nonqueued-receiver-com-spec{data-element=PosLrnd/Val, filter=data-filter-type=ALWAYS, init-value=0}, required-interface=PosLrnd
      AcsEntry4s2RPosLrnd: nonqueued-receiver-com-spec{data-element=PosLrnd/Val, filter=data-filter-type=ALWAYS, init-value=0}, required-interface=PosLrnd
      AcsEntryAll4sBwdPosLrnd: nonqueued-receiver-com-spec{data-element=PosLrnd/Val, filter=data-filter-type=ALWAYS, init-value=0}, required-interface=PosLrnd
      AcsEntryAll4sFwdPosLrnd: nonqueued-receiver-com-spec{data-element=PosLrnd/Val, filter=data-filter-type=ALWAYS, init-value=0}, required-interface=PosLrnd
      AcsEntryPosLrnd: nonqueued-receiver-com-spec{data-element=PosLrnd/Val, filter=data-filter-type=ALWAYS, init-value=0}, required-interface=PosLrnd
      AcsExit4s2LPosLrnd: nonqueued-receiver-com-spec{data-element=PosLrnd/Val, filter=data-filter-type=ALWAYS, init-value=0}, required-interface=PosLrnd
      AcsExit4s2RPosLrnd: nonqueued-receiver-com-spec{data-element=PosLrnd/Val, filter=data-filter-type=ALWAYS, init-value=0}, required-interface=PosLrnd
      AcsExitPosLrnd: nonqueued-receiver-com-spec{data-element=PosLrnd/Val, filter=data-filter-type=ALWAYS, init-value=0}, required-interface=PosLrnd
      DrvStPosRclRspStat: nonqueued-receiver-com-spec{data-element=PosRclRspStat/Val, filter=data-filter-type=ALWAYS, init-value=0}, required-interface=PosRclRspStat
      EnergyMgLdShdRq: nonqueued-receiver-com-spec{data-element=EnergyMgLdShdRq/Val, filter=data-filter-type=ALWAYS, init-value=0}, required-interface=EnergyMgLdShdRq
      FamilyLtPosLrnd: nonqueued-receiver-com-spec{data-element=PosLrnd/Val, filter=data-filter-type=ALWAYS, init-value=0}, required-interface=PosLrnd
      FamilyRtPosLrnd: nonqueued-receiver-com-spec{data-element=PosLrnd/Val, filter=data-filter-type=ALWAYS, init-value=0}, required-interface=PosLrnd
      HMI_2L_StMd1_Config: parameter-require-com-spec{init-value=0, parameter=KeSMSbHMICfg/Val}, required-interface=KeSMSbHMICfg
      HMI_2L_StMd{10..19}_Config: parameter-require-com-spec{init-value=0, parameter=KeSMSbHMICfg/Val}, required-interface=KeSMSbHMICfg
      HMI_2L_StMd2_Config: parameter-require-com-spec{init-value=0, parameter=KeSMSbHMICfg/Val}, required-interface=KeSMSbHMICfg
      HMI_2L_StMd{20..29}_Config: parameter-require-com-spec{init-value=0, parameter=KeSMSbHMICfg/Val}, required-interface=KeSMSbHMICfg
      HMI_2L_StMd3_Config: parameter-require-com-spec{init-value=0, parameter=KeSMSbHMICfg/Val}, required-interface=KeSMSbHMICfg
      HMI_2L_StMd{30..32}_Config: parameter-require-com-spec{init-value=0, parameter=KeSMSbHMICfg/Val}, required-interface=KeSMSbHMICfg
      HMI_2L_StMd{4..9}_Config: parameter-require-com-spec{init-value=0, parameter=KeSMSbHMICfg/Val}, required-interface=KeSMSbHMICfg
      HMI_2R_StMd1_Config: parameter-require-com-spec{init-value=0, parameter=KeSMSbHMICfg/Val}, required-interface=KeSMSbHMICfg
      HMI_2R_StMd{10..19}_Config: parameter-require-com-spec{init-value=0, parameter=KeSMSbHMICfg/Val}, required-interface=KeSMSbHMICfg
      HMI_2R_StMd2_Config: parameter-require-com-spec{init-value=0, parameter=KeSMSbHMICfg/Val}, required-interface=KeSMSbHMICfg
      HMI_2R_StMd{20..29}_Config: parameter-require-com-spec{init-value=0, parameter=KeSMSbHMICfg/Val}, required-interface=KeSMSbHMICfg
      HMI_2R_StMd3_Config: parameter-require-com-spec{init-value=0, parameter=KeSMSbHMICfg/Val}, required-interface=KeSMSbHMICfg
      HMI_2R_StMd{30..32}_Config: parameter-require-com-spec{init-value=0, parameter=KeSMSbHMICfg/Val}, required-interface=KeSMSbHMICfg
      HMI_2R_StMd{4..9}_Config: parameter-require-com-spec{init-value=0, parameter=KeSMSbHMICfg/Val}, required-interface=KeSMSbHMICfg
      IfKeSMSbSeatMovFrwdBkwdEnable: parameter-require-com-spec{init-value=1, parameter=SeatMovCfg/Val}, required-interface=SeatMovCfg
      IfVeSMSbPasReclinerPosAvail: nonqueued-receiver-com-spec{data-element=PosAvail/Val, filter=data-filter-type=ALWAYS, init-value=0}, required-interface=PosAvail
      IfVeSMSbPassReclinerPosLrnd: nonqueued-receiver-com-spec{data-element=PosLrnd/Val, filter=data-filter-type=ALWAYS, init-value=0}, required-interface=PosLrnd
      IfVeSMSbSecRwLtStBkReclnUpwdDnwdPosV: nonqueued-receiver-com-spec{data-element=IfVeSMSbSecRwLtStBkReclnUpwdDnwdPosV/Val, filter=data-filter-type=ALWAYS, init-value=0}, required-interface=IfVeSMSbSecRwLtStBkReclnUpwdDnwdPosV
      IfVeSMSbSecRwRtStBkReclnUpwdDnwdPosV: nonqueued-receiver-com-spec{data-element=IfVeSMSbSecRwRtStBkReclnUpwdDnwdPosV/Val, filter=data-filter-type=ALWAYS, init-value=0}, required-interface=IfVeSMSbSecRwRtStBkReclnUpwdDnwdPosV
      IfVeSMSbunfold3LPosLrnd: nonqueued-receiver-com-spec{data-element=PosLrnd/Val, filter=data-filter-type=ALWAYS, init-value=0}, required-interface=PosLrnd
      IfVeSMSbunfold3RPosLrnd: nonqueued-receiver-com-spec{data-element=PosLrnd/Val, filter=data-filter-type=ALWAYS, init-value=0}, required-interface=PosLrnd
      IfVeSMSbVIPLtOutPosLrnd: nonqueued-receiver-com-spec{data-element=PosLrnd/Val, filter=data-filter-type=ALWAYS, init-value=0}, required-interface=PosLrnd
      IfVeSMSbVIPRtOutPosLrnd: nonqueued-receiver-com-spec{data-element=PosLrnd/Val, filter=data-filter-type=ALWAYS, init-value=0}, required-interface=PosLrnd
      IfVeSMSeStNumConfig: nonqueued-receiver-com-spec{data-element=IfVeSMSeStNumConfig/Val, filter=data-filter-type=ALWAYS, init-value=2}, required-interface=IfVeSMSeStNumConfig
      IfVeSMSuSecRwLtStBkReclnUpwdDnwdPos: nonqueued-receiver-com-spec{data-element=IfVeSMSuSecRwLtStBkReclnUpwdDnwdPos/Val, filter=data-filter-type=ALWAYS, init-value=0}, required-interface=IfVeSMSuSecRwLtStBkReclnUpwdDnwdPos
      IfVeSMSuSecRwRtStBkReclnUpwdDnwdPos: nonqueued-receiver-com-spec{data-element=IfVeSMSuSecRwRtStBkReclnUpwdDnwdPos/Val, filter=data-filter-type=ALWAYS, init-value=0}, required-interface=IfVeSMSuSecRwRtStBkReclnUpwdDnwdPos
      IfVeSMSuThdRwLtStCshnFldUpwdDnwdPos: nonqueued-receiver-com-spec{data-element=IfVeSMSuThdRwLtStCshnFldUpwdDnwdPos/Val, filter=data-filter-type=ALWAYS, init-value=0}, required-interface=IfVeSMSuThdRwLtStCshnFldUpwdDnwdPos
      IfVeSMSuThdRwLtStCshnFldUpwdDnwdPosV: nonqueued-receiver-com-spec{data-element=IfVeSMSuThdRwLtStCshnFldUpwdDnwdPosV/Val, filter=data-filter-type=ALWAYS, init-value=0}, required-interface=IfVeSMSuThdRwLtStCshnFldUpwdDnwdPosV
      IfVeSMSuThdRwRtStCshnFldUpwdDnwdPos: nonqueued-receiver-com-spec{data-element=IfVeSMSuThdRwRtStCshnFldUpwdDnwdPos/Val, filter=data-filter-type=ALWAYS, init-value=0}, required-interface=IfVeSMSuThdRwRtStCshnFldUpwdDnwdPos
      IfVeSMSuThdRwRtStCshnFldUpwdDnwdPosV: nonqueued-receiver-com-spec{data-element=IfVeSMSuThdRwRtStCshnFldUpwdDnwdPosV/Val, filter=data-filter-type=ALWAYS, init-value=0}, required-interface=IfVeSMSuThdRwRtStCshnFldUpwdDnwdPosV
      IntimacyLPosLrnd: nonqueued-receiver-com-spec{data-element=PosLrnd/Val, filter=data-filter-type=ALWAYS, init-value=0}, required-interface=PosLrnd
      IntimacyRPosLrnd: nonqueued-receiver-com-spec{data-element=PosLrnd/Val, filter=data-filter-type=ALWAYS, init-value=0}, required-interface=PosLrnd
      Is2LStSwAct: nonqueued-receiver-com-spec{data-element=SeatSwActive/Val, filter=data-filter-type=ALWAYS, init-value=0}, required-interface=SeatSwActive
      Is2RStSwAct: nonqueued-receiver-com-spec{data-element=SeatSwActive/Val, filter=data-filter-type=ALWAYS, init-value=0}, required-interface=SeatSwActive
      Is3LStSwAct: nonqueued-receiver-com-spec{data-element=SeatSwActive/Val, filter=data-filter-type=ALWAYS, init-value=0}, required-interface=SeatSwActive
      Is3RStSwAct: nonqueued-receiver-com-spec{data-element=SeatSwActive/Val, filter=data-filter-type=ALWAYS, init-value=0}, required-interface=SeatSwActive
      IsDrvStSwAct: nonqueued-receiver-com-spec{data-element=SeatSwActive/Val, filter=data-filter-type=ALWAYS, init-value=0}, required-interface=SeatSwActive
      IsPasStSwAct: nonqueued-receiver-com-spec{data-element=SeatSwActive/Val, filter=data-filter-type=ALWAYS, init-value=0}, required-interface=SeatSwActive
      KeSMSbRoofSWEnable: parameter-require-com-spec{init-value=0, parameter=SeatEnable/Val}, required-interface=SeatEnable
      KeSMSLegrstDisFwdBkwdPos: parameter-require-com-spec{init-value=4000, parameter=KeSMSLegrstDisFwdBkwdPos/Val}, required-interface=KeSMSLegrstDisFwdBkwdPos
      KeSMSuSecRwStBackPosDelta: parameter-require-com-spec{init-value=40, parameter=KeSMSwDltPos/Val}, required-interface=KeSMSwDltPos
      KeSMSuThrdRwCushFoldPosDelta: parameter-require-com-spec{init-value=150, parameter=MdPosDelta/Val}, required-interface=MdPosDelta
      KeSMSuThrdRwCushFoldPosThreshold: parameter-require-com-spec{init-value=2800, parameter=MdPosDelta/Val}, required-interface=MdPosDelta
      KeSMSwAcsMd32SecRwLtStBkReclnUpwdDnwdPos1: parameter-require-com-spec{init-value=0, parameter=Pos/Val}, required-interface=Pos
      KeSMSwAcsMd53SecRwRtStBkReclnUpwdDnwdPos1: parameter-require-com-spec{init-value=0, parameter=Pos/Val}, required-interface=Pos
      KeSMSwAcsMd8SecRwLtStBkReclnUpwdDnwdPos: parameter-require-com-spec{init-value=0, parameter=Pos/Val}, required-interface=Pos
      KeSMSwAcsMd9SecRwRtStBkReclnUpwdDnwdPos: parameter-require-com-spec{init-value=0, parameter=Pos/Val}, required-interface=Pos
      KeSMSwSeatBkLimitPos: parameter-require-com-spec{init-value=2052, parameter=MdPosDelta/Val}, required-interface=MdPosDelta
      KeSMSwSeatBkLimitPosDelt: parameter-require-com-spec{init-value=120, parameter=MdPosDelta/Val}, required-interface=MdPosDelta
      LgrstCloseLtPosLrnd: nonqueued-receiver-com-spec{data-element=PosLrnd/Val, filter=data-filter-type=ALWAYS, init-value=0}, required-interface=PosLrnd
      LgrstCloseRtPosLrnd: nonqueued-receiver-com-spec{data-element=PosLrnd/Val, filter=data-filter-type=ALWAYS, init-value=0}, required-interface=PosLrnd
      LgrstOpenLtPosLrnd: nonqueued-receiver-com-spec{data-element=PosLrnd/Val, filter=data-filter-type=ALWAYS, init-value=0}, required-interface=PosLrnd
      LgrstOpenRtPosLrnd: nonqueued-receiver-com-spec{data-element=PosLrnd/Val, filter=data-filter-type=ALWAYS, init-value=0}, required-interface=PosLrnd
      LugLtPosLrnd: nonqueued-receiver-com-spec{data-element=PosLrnd/Val, filter=data-filter-type=ALWAYS, init-value=0}, required-interface=PosLrnd
      LugRtPosLrnd: nonqueued-receiver-com-spec{data-element=PosLrnd/Val, filter=data-filter-type=ALWAYS, init-value=0}, required-interface=PosLrnd
      LyingLtPosLrnd: nonqueued-receiver-com-spec{data-element=PosLrnd/Val, filter=data-filter-type=ALWAYS, init-value=0}, required-interface=PosLrnd
      LyingRtPosLrnd: nonqueued-receiver-com-spec{data-element=PosLrnd/Val, filter=data-filter-type=ALWAYS, init-value=0}, required-interface=PosLrnd
      Md61PassStBkReclnTrgtPos: nonqueued-receiver-com-spec{data-element=PercPos/Val, filter=data-filter-type=ALWAYS, init-value=0}, required-interface=PercPos
      Md61ThdRwLtStCshnFldUpwdDnwdTrgtPos: nonqueued-receiver-com-spec{data-element=PercPos/Val, filter=data-filter-type=ALWAYS, init-value=0}, required-interface=PercPos
      Md61ThdRwRtStCshnFldUpwdDnwdTrgtPos: nonqueued-receiver-com-spec{data-element=PercPos/Val, filter=data-filter-type=ALWAYS, init-value=0}, required-interface=PercPos
      Md62PassStBkReclnTrgtPos: nonqueued-receiver-com-spec{data-element=PercPos/Val, filter=data-filter-type=ALWAYS, init-value=0}, required-interface=PercPos
      Md62ThdRwLtStCshnFldUpwdDnwdTrgtPos: nonqueued-receiver-com-spec{data-element=PercPos/Val, filter=data-filter-type=ALWAYS, init-value=0}, required-interface=PercPos
      Md62ThdRwRtStCshnFldUpwdDnwdTrgtPos: nonqueued-receiver-com-spec{data-element=PercPos/Val, filter=data-filter-type=ALWAYS, init-value=0}, required-interface=PercPos
      MmryRclImpctDisRq: nonqueued-receiver-com-spec{data-element=IfVeSMSuMmryRclImpctDisRq/Val, filter=data-filter-type=ALWAYS, init-value=1}, required-interface=IfVeSMSuMmryRclImpctDisRq
      NotCoDrvStOccStatBDFSrc: nonqueued-receiver-com-spec{data-element=SeatOccupiedState/Val, filter=data-filter-type=ALWAYS, init-value=0}, required-interface=SeatOccupiedState
      NotSecRowLeStOccStatBDFSrc: nonqueued-receiver-com-spec{data-element=SeatOccupiedState/Val, filter=data-filter-type=ALWAYS, init-value=0}, required-interface=SeatOccupiedState
      NotSecRowRtStOccStatBDFSrc: nonqueued-receiver-com-spec{data-element=SeatOccupiedState/Val, filter=data-filter-type=ALWAYS, init-value=0}, required-interface=SeatOccupiedState
      PassStPosRclRspStat: nonqueued-receiver-com-spec{data-element=PosRclRspStat/Val, filter=data-filter-type=ALWAYS, init-value=0}, required-interface=PosRclRspStat
      RcvyLtPosLrnd: nonqueued-receiver-com-spec{data-element=PosLrnd/Val, filter=data-filter-type=ALWAYS, init-value=0}, required-interface=PosLrnd
      RcvyRtPosLrnd: nonqueued-receiver-com-spec{data-element=PosLrnd/Val, filter=data-filter-type=ALWAYS, init-value=0}, required-interface=PosLrnd
      SecRwLtStChldLkReq: nonqueued-receiver-com-spec{data-element=IfVeSMSeSecRwLtStChldLkReq/Val, filter=data-filter-type=ALWAYS, init-value=0}, required-interface=IfVeSMSeSecRwLtStChldLkReq
      SecRwLtStFrwdBkwdPos: nonqueued-receiver-com-spec{data-element=IfVeSMSuSecRwLtStFrwdBkwdPos/Val, filter=data-filter-type=ALWAYS, init-value=0}, required-interface=IfVeSMSuSecRwLtStFrwdBkwdPos
      SecRwLtStFrwdBkwdPosV: nonqueued-receiver-com-spec{data-element=IfVeSMSbSecRwLtStFrwdBkwdPosV/Val, filter=data-filter-type=ALWAYS, init-value=0}, required-interface=IfVeSMSbSecRwLtStFrwdBkwdPosV
      SecRwLtStPosRclRspStat: nonqueued-receiver-com-spec{data-element=PosRclRspStat/Val, filter=data-filter-type=ALWAYS, init-value=0}, required-interface=PosRclRspStat
      SecRwRtStChldLkReq: nonqueued-receiver-com-spec{data-element=IfVeSMSeSecRwRtStChldLkReq/Val, filter=data-filter-type=ALWAYS, init-value=0}, required-interface=IfVeSMSeSecRwRtStChldLkReq
      SecRwRtStFrwdBkwdPos: nonqueued-receiver-com-spec{data-element=PercPos/Val, filter=data-filter-type=ALWAYS, init-value=0}, required-interface=PercPos
      SecRwRtStFrwdBkwdPosV: nonqueued-receiver-com-spec{data-element=IfVeSMSbSecRwRtStFrwdBkwdPosV/Val, filter=data-filter-type=ALWAYS, init-value=0}, required-interface=IfVeSMSbSecRwRtStFrwdBkwdPosV
      SecRwRtStPosRclRspStat: nonqueued-receiver-com-spec{data-element=PosRclRspStat/Val, filter=data-filter-type=ALWAYS, init-value=0}, required-interface=PosRclRspStat
      StPassCmprtMdCtrl_Md1_VCUConfig: parameter-require-com-spec{init-value=0, parameter=KeSMSbStPassCmprtMdVCUCfg/Val}, required-interface=KeSMSbStPassCmprtMdVCUCfg
      StPassCmprtMdCtrl_Md{10..19}_VCUConfig: parameter-require-com-spec{init-value=0, parameter=KeSMSbStPassCmprtMdVCUCfg/Val}, required-interface=KeSMSbStPassCmprtMdVCUCfg
      StPassCmprtMdCtrl_Md2_VCUConfig: parameter-require-com-spec{init-value=0, parameter=KeSMSbStPassCmprtMdVCUCfg/Val}, required-interface=KeSMSbStPassCmprtMdVCUCfg
      StPassCmprtMdCtrl_Md{20..29}_VCUConfig: parameter-require-com-spec{init-value=0, parameter=KeSMSbStPassCmprtMdVCUCfg/Val}, required-interface=KeSMSbStPassCmprtMdVCUCfg
      StPassCmprtMdCtrl_Md3_VCUConfig: parameter-require-com-spec{init-value=0, parameter=KeSMSbStPassCmprtMdVCUCfg/Val}, required-interface=KeSMSbStPassCmprtMdVCUCfg
      StPassCmprtMdCtrl_Md{30..32}_VCUConfig: parameter-require-com-spec{init-value=0, parameter=KeSMSbStPassCmprtMdVCUCfg/Val}, required-interface=KeSMSbStPassCmprtMdVCUCfg
      StPassCmprtMdCtrl_Md4_VCUConfig: parameter-require-com-spec{init-value=0, parameter=KeSMSbStPassCmprtMdVCUCfg/Val}, required-interface=KeSMSbStPassCmprtMdVCUCfg
      StPassCmprtMdCtrl_Md5_VCUConfig: parameter-require-com-spec{init-value=0, parameter=KeSMSbStPassCmprtMdVCUCfg/Val}, required-interface=KeSMSbStPassCmprtMdVCUCfg
      StPassCmprtMdCtrl_Md53_VCUConfig: parameter-require-com-spec{init-value=0, parameter=KeSMSbStPassCmprtMdVCUCfg/Val}, required-interface=KeSMSbStPassCmprtMdVCUCfg
      StPassCmprtMdCtrl_Md{56..58}_VCUConfig: parameter-require-com-spec{init-value=0, parameter=KeSMSbStPassCmprtMdVCUCfg/Val}, required-interface=KeSMSbStPassCmprtMdVCUCfg
      StPassCmprtMdCtrl_Md6_VCUConfig: parameter-require-com-spec{init-value=0, parameter=KeSMSbStPassCmprtMdVCUCfg/Val}, required-interface=KeSMSbStPassCmprtMdVCUCfg
      StPassCmprtMdCtrl_Md61_VCUConfig: parameter-require-com-spec{init-value=0, parameter=KeSMSbStPassCmprtMdVCUCfg/Val}, required-interface=KeSMSbStPassCmprtMdVCUCfg
      StPassCmprtMdCtrl_Md62_VCUConfig: parameter-require-com-spec{init-value=0, parameter=KeSMSbStPassCmprtMdVCUCfg/Val}, required-interface=KeSMSbStPassCmprtMdVCUCfg
      StPassCmprtMdCtrl_Md{7..9}_VCUConfig: parameter-require-com-spec{init-value=0, parameter=KeSMSbStPassCmprtMdVCUCfg/Val}, required-interface=KeSMSbStPassCmprtMdVCUCfg
      StSrv_StMd1_Config: parameter-require-com-spec{init-value=0, parameter=KeSMSbStSrvCfg/Val}, required-interface=KeSMSbStSrvCfg
      StSrv_StMd{10..19}_Config: parameter-require-com-spec{init-value=0, parameter=KeSMSbStSrvCfg/Val}, required-interface=KeSMSbStSrvCfg
      StSrv_StMd2_Config: parameter-require-com-spec{init-value=0, parameter=KeSMSbStSrvCfg/Val}, required-interface=KeSMSbStSrvCfg
      StSrv_StMd{20..29}_Config: parameter-require-com-spec{init-value=0, parameter=KeSMSbStSrvCfg/Val}, required-interface=KeSMSbStSrvCfg
      StSrv_StMd3_Config: parameter-require-com-spec{init-value=0, parameter=KeSMSbStSrvCfg/Val}, required-interface=KeSMSbStSrvCfg
      StSrv_StMd{30..32}_Config: parameter-require-com-spec{init-value=0, parameter=KeSMSbStSrvCfg/Val}, required-interface=KeSMSbStSrvCfg
      StSrv_StMd{4..9}_Config: parameter-require-com-spec{init-value=0, parameter=KeSMSbStSrvCfg/Val}, required-interface=KeSMSbStSrvCfg
      SysPwrMd: nonqueued-receiver-com-spec{data-element=PowerMode/Val, filter=data-filter-type=ALWAYS, init-value=0}, required-interface=PowerMode
      SysPwrMdV: nonqueued-receiver-com-spec{data-element=Validity/Val, filter=data-filter-type=ALWAYS, init-value=0}, required-interface=Validity
      ThdRwCtStOccStatMSMSrc: nonqueued-receiver-com-spec{data-element=SeatOccupiedState/Val, filter=data-filter-type=ALWAYS, init-value=0}, required-interface=SeatOccupiedState
      ThdRwLtStChldLkReq: nonqueued-receiver-com-spec{data-element=IfVeSMSeThdRwLtStChldLkReq/Val, filter=data-filter-type=ALWAYS, init-value=2}, required-interface=IfVeSMSeThdRwLtStChldLkReq
      ThdRwLtStOccStatMSMSrc: nonqueued-receiver-com-spec{data-element=SeatOccupiedState/Val, filter=data-filter-type=ALWAYS, init-value=0}, required-interface=SeatOccupiedState
      ThdRwLtStPosRclRspStat: nonqueued-receiver-com-spec{data-element=PosRclRspStat/Val, filter=data-filter-type=ALWAYS, init-value=0}, required-interface=PosRclRspStat
      ThdRwRtStOccStatMSMSrc: nonqueued-receiver-com-spec{data-element=SeatOccupiedState/Val, filter=data-filter-type=ALWAYS, init-value=0}, required-interface=SeatOccupiedState
      ThdRwRtStPosRclRspStat: nonqueued-receiver-com-spec{data-element=PosRclRspStat/Val, filter=data-filter-type=ALWAYS, init-value=0}, required-interface=PosRclRspStat
      VehMovState: nonqueued-receiver-com-spec{data-element=VehMovState/Val, filter=data-filter-type=ALWAYS, init-value=0}, required-interface=VehMovState
      VehSpdAvgDrvn: nonqueued-receiver-com-spec{data-element=VehSpeed/Val, filter=data-filter-type=ALWAYS, init-value=0}, required-interface=VehSpeed
      VehSpdAvgDrvnV: nonqueued-receiver-com-spec{data-element=Validity/Val, filter=data-filter-type=ALWAYS, init-value=0}, required-interface=Validity
      VeSignalLost2R_463_2L: nonqueued-receiver-com-spec{data-element=VeSignalLost_DataTpye/Val, filter=data-filter-type=ALWAYS, init-value=0}, required-interface=VeSignalLost_DataTpye
      VeSignalLost3L_468_2L: nonqueued-receiver-com-spec{data-element=VeSignalLost_DataTpye/Val, filter=data-filter-type=ALWAYS, init-value=0}, required-interface=VeSignalLost_DataTpye
      VeSignalLost3R_46C_2L: nonqueued-receiver-com-spec{data-element=VeSignalLost_DataTpye/Val, filter=data-filter-type=ALWAYS, init-value=0}, required-interface=VeSignalLost_DataTpye
      VeSignalLostCODR_470_2L: nonqueued-receiver-com-spec{data-element=VeSignalLost_DataTpye/Val, filter=data-filter-type=ALWAYS, init-value=0}, required-interface=VeSignalLost_DataTpye
      VeSignalLostDR_213_2L: nonqueued-receiver-com-spec{data-element=VeSignalLost_DataTpye/Val, filter=data-filter-type=ALWAYS, init-value=0}, required-interface=VeSignalLost_DataTpye
      VeSignalLostFireWall_1D2_2L: nonqueued-receiver-com-spec{data-element=VeSignalLost_DataTpye/Val, filter=data-filter-type=ALWAYS, init-value=0}, required-interface=VeSignalLost_DataTpye
      VeSignalLostSDM_195_2L: nonqueued-receiver-com-spec{data-element=VeSignalLost_DataTpye/Val, filter=data-filter-type=ALWAYS, init-value=0}, required-interface=VeSignalLost_DataTpye
      VIPLtPosLrnd: nonqueued-receiver-com-spec{data-element=PosLrnd/Val, filter=data-filter-type=ALWAYS, init-value=0}, required-interface=PosLrnd
      VIPRtPosLrnd: nonqueued-receiver-com-spec{data-element=PosLrnd/Val, filter=data-filter-type=ALWAYS, init-value=0}, required-interface=PosLrnd
      VoltSts: nonqueued-receiver-com-spec{data-element=VoltSts/Val, filter=data-filter-type=ALWAYS, init-value=0}, required-interface=VoltSts
      WholeVehMemPosLrnd: nonqueued-receiver-com-spec{data-element=PosLrnd/Val, filter=data-filter-type=ALWAYS, init-value=0}, required-interface=PosLrnd
    behavior PreCondition_InternalBehavior
      timing event TMT_PreConitionRunnable: start-on-event=PreConitionRunnable, period=0.01
      runnable PreConitionRunnable
        data-receive-point-by-arguments:
          88 x access:
            REC_AbgDplyBckp_Val: accessed-variable=AbgDplyBckp.Val
            REC_AbgDplyBckpV_Val: accessed-variable=AbgDplyBckpV.Val
            REC_AcsEntry4s2LPosLrnd_Val: accessed-variable=AcsEntry4s2LPosLrnd.Val
            REC_AcsEntry4s2RPosLrnd_Val: accessed-variable=AcsEntry4s2RPosLrnd.Val
            REC_AcsEntryAll4sBwdPosLrnd_Val: accessed-variable=AcsEntryAll4sBwdPosLrnd.Val
            REC_AcsEntryAll4sFwdPosLrnd_Val: accessed-variable=AcsEntryAll4sFwdPosLrnd.Val
            REC_AcsExit4s2LPosLrnd_Val: accessed-variable=AcsExit4s2LPosLrnd.Val
            REC_AcsExit4s2RPosLrnd_Val: accessed-variable=AcsExit4s2RPosLrnd.Val
            REC_DrvStPosLrnd_Val: accessed-variable=AcsEntryPosLrnd.Val
            REC_DrvStPosRclRspStat_Val: accessed-variable=DrvStPosRclRspStat.Val
            REC_EnergyMgLdShdRq_Val: accessed-variable=EnergyMgLdShdRq.Val
            REC_FamilyLtPosLrnd_Val: accessed-variable=FamilyLtPosLrnd.Val
            REC_FamilyRtPosLrnd_Val: accessed-variable=FamilyRtPosLrnd.Val
            REC_IfVeSMSbPasReclinerPosAvail_Val: accessed-variable=IfVeSMSbPasReclinerPosAvail.Val
            REC_IfVeSMSbPassReclinerPosLrnd_Val: accessed-variable=IfVeSMSbPassReclinerPosLrnd.Val
            REC_IfVeSMSbSecRwLtStBkReclnUpwdDnwdPosV_Val: accessed-variable=IfVeSMSbSecRwLtStBkReclnUpwdDnwdPosV.Val
            REC_IfVeSMSbSecRwRtStBkReclnUpwdDnwdPosV_Val: accessed-variable=IfVeSMSbSecRwRtStBkReclnUpwdDnwdPosV.Val
            REC_IfVeSMSbunfold3LPosLrnd_Val: accessed-variable=IfVeSMSbunfold3LPosLrnd.Val
            REC_IfVeSMSbunfold3RPosLrnd_Val: accessed-variable=IfVeSMSbunfold3RPosLrnd.Val
            REC_IfVeSMSbVIPLtOutPosLrnd_Val: accessed-variable=IfVeSMSbVIPLtOutPosLrnd.Val
            REC_IfVeSMSbVIPRtOutPosLrnd_Val: accessed-variable=IfVeSMSbVIPRtOutPosLrnd.Val
            REC_IfVeSMSeStNumConfig_Val: accessed-variable=IfVeSMSeStNumConfig.Val
            REC_IfVeSMSuSecRwLtStBkReclnUpwdDnwdPos_Val: accessed-variable=IfVeSMSuSecRwLtStBkReclnUpwdDnwdPos.Val
            REC_IfVeSMSuSecRwRtStBkReclnUpwdDnwdPos_Val: accessed-variable=IfVeSMSuSecRwRtStBkReclnUpwdDnwdPos.Val
            REC_IfVeSMSuThdRwLtStCshnFldUpwdDnwdPos_Val: accessed-variable=IfVeSMSuThdRwLtStCshnFldUpwdDnwdPos.Val
            REC_IfVeSMSuThdRwLtStCshnFldUpwdDnwdPosV_Val: accessed-variable=IfVeSMSuThdRwLtStCshnFldUpwdDnwdPosV.Val
            REC_IfVeSMSuThdRwRtStCshnFldUpwdDnwdPos_Val: accessed-variable=IfVeSMSuThdRwRtStCshnFldUpwdDnwdPos.Val
            REC_IfVeSMSuThdRwRtStCshnFldUpwdDnwdPosV_Val: accessed-variable=IfVeSMSuThdRwRtStCshnFldUpwdDnwdPosV.Val
            REC_IntimacyPosLrnd_Val: accessed-variable=IntimacyLPosLrnd.Val
            REC_IntimacyRPosLrnd_Val: accessed-variable=IntimacyRPosLrnd.Val
            REC_Is2LStSwAct_Val: accessed-variable=Is2LStSwAct.Val
            REC_Is2RStSwAct_Val: accessed-variable=Is2RStSwAct.Val
            REC_Is3LStSwAct_Val: accessed-variable=Is3LStSwAct.Val
            REC_Is3RStSwAct_Val: accessed-variable=Is3RStSwAct.Val
            REC_IsDrvStSwAct_Val: accessed-variable=IsDrvStSwAct.Val
            REC_IsPasStSwAct_Val: accessed-variable=IsPasStSwAct.Val
            REC_LgrstCloseLtPosLrnd_Val: accessed-variable=LgrstCloseLtPosLrnd.Val
            REC_LgrstCloseRtPosLrnd_Val: accessed-variable=LgrstCloseRtPosLrnd.Val
            REC_LgrstOpenLtPosLrnd_Val: accessed-variable=LgrstOpenLtPosLrnd.Val
            REC_LgrstOpenRtPosLrnd_Val: accessed-variable=LgrstOpenRtPosLrnd.Val
            REC_LugLtPosLrnd_Val: accessed-variable=LugLtPosLrnd.Val
            REC_LugRtPosLrnd_Val: accessed-variable=LugRtPosLrnd.Val
            REC_LyingLtPosLrnd_Val: accessed-variable=LyingLtPosLrnd.Val
            REC_LyingRtPosLrnd_Val: accessed-variable=LyingRtPosLrnd.Val
            REC_Md61PassStBkReclnTrgtPos_Val: accessed-variable=Md61PassStBkReclnTrgtPos.Val
            REC_Md61ThdRwLtStCshnFldUpwdDnwdTrgtPos_Val: accessed-variable=Md61ThdRwLtStCshnFldUpwdDnwdTrgtPos.Val
            REC_Md61ThdRwRtStCshnFldUpwdDnwdTrgtPos_Val: accessed-variable=Md61ThdRwRtStCshnFldUpwdDnwdTrgtPos.Val
            REC_Md62PassStBkReclnTrgtPos_Val: accessed-variable=Md62PassStBkReclnTrgtPos.Val
            REC_Md62ThdRwLtStCshnFldUpwdDnwdTrgtPos_Val: accessed-variable=Md62ThdRwLtStCshnFldUpwdDnwdTrgtPos.Val
            REC_Md62ThdRwRtStCshnFldUpwdDnwdTrgtPos_Val: accessed-variable=Md62ThdRwRtStCshnFldUpwdDnwdTrgtPos.Val
            REC_MmryRclImpctDisRq_Val: accessed-variable=MmryRclImpctDisRq.Val
            REC_NotCoDrvStOccStatBDFSrc_Val: accessed-variable=NotCoDrvStOccStatBDFSrc.Val
            REC_NotSecRowLeStOccStatBDFSrc_Val: accessed-variable=NotSecRowLeStOccStatBDFSrc.Val
            REC_NotSecRowRtStOccStatBDFSrc_Val: accessed-variable=NotSecRowRtStOccStatBDFSrc.Val
            REC_PassStPosLrnd_Val: accessed-variable=AcsExitPosLrnd.Val
            REC_PassStPosRclRspStat_Val: accessed-variable=PassStPosRclRspStat.Val
            REC_SecRwLtPosLrnd_Val: accessed-variable=VIPLtPosLrnd.Val
            REC_SecRwLtStChldLkReq_Val: accessed-variable=SecRwLtStChldLkReq.Val
            REC_SecRwLtStFrwdBkwdPos_Val: accessed-variable=SecRwLtStFrwdBkwdPos.Val
            REC_SecRwLtStFrwdBkwdPosV_Val: accessed-variable=SecRwLtStFrwdBkwdPosV.Val
            REC_SecRwLtStPosRclRspStat_Val: accessed-variable=SecRwLtStPosRclRspStat.Val
            REC_SecRwRtPosLrnd_Val: accessed-variable=VIPRtPosLrnd.Val
            REC_SecRwRtStChldLkReq_Val: accessed-variable=SecRwRtStChldLkReq.Val
            REC_SecRwRtStFrwdBkwdPos_Val: accessed-variable=SecRwRtStFrwdBkwdPos.Val
            REC_SecRwRtStFrwdBkwdPosV_Val: accessed-variable=SecRwRtStFrwdBkwdPosV.Val
            REC_SecRwRtStPosRclRspStat_Val: accessed-variable=SecRwRtStPosRclRspStat.Val
            REC_SysPwrMd_Val: accessed-variable=SysPwrMd.Val
            REC_SysPwrMdV_Val: accessed-variable=SysPwrMdV.Val
            REC_ThdRwCtStOccStatMSMSrc_Val: accessed-variable=ThdRwCtStOccStatMSMSrc.Val
            REC_ThdRwLtPosLrnd_Val: accessed-variable=RcvyLtPosLrnd.Val
            REC_ThdRwLtStChldLkReq_Val: accessed-variable=ThdRwLtStChldLkReq.Val
            REC_ThdRwLtStOccStatMSMSrc_Val: accessed-variable=ThdRwLtStOccStatMSMSrc.Val
            REC_ThdRwLtStPosRclRspStat_Val: accessed-variable=ThdRwLtStPosRclRspStat.Val
            REC_ThdRwRtPosLrnd_Val: accessed-variable=RcvyRtPosLrnd.Val
            REC_ThdRwRtStOccStatMSMSrc_Val: accessed-variable=ThdRwRtStOccStatMSMSrc.Val
            REC_ThdRwRtStPosRclRspStat_Val: accessed-variable=ThdRwRtStPosRclRspStat.Val
            REC_VehMovState_Val: accessed-variable=VehMovState.Val
            REC_VehSpdAvgDrvn_Val: accessed-variable=VehSpdAvgDrvn.Val
            REC_VehSpdAvgDrvnV_Val: accessed-variable=VehSpdAvgDrvnV.Val
            REC_VeSignalLost2R_463_2L_Val: accessed-variable=VeSignalLost2R_463_2L.Val
            REC_VeSignalLost3L_468_2L_Val: accessed-variable=VeSignalLost3L_468_2L.Val
            REC_VeSignalLost3R_46C_2L_Val: accessed-variable=VeSignalLost3R_46C_2L.Val
            REC_VeSignalLostCODR_470_2L_Val: accessed-variable=VeSignalLostCODR_470_2L.Val
            REC_VeSignalLostDR_213_2L_Val: accessed-variable=VeSignalLostDR_213_2L.Val
            REC_VeSignalLostFireWall_1D2_2L_Val: accessed-variable=VeSignalLostFireWall_1D2_2L.Val
            REC_VeSignalLostSDM_195_2L_Val: accessed-variable=VeSignalLostSDM_195_2L.Val
            REC_VoltSts_VoltSts: accessed-variable=VoltSts.Val
            REC_WholeVehMemPosLrnd_Val: accessed-variable=WholeVehMemPosLrnd.Val
        data-send-points:
          309 x access:
            SEND_AcsEntry4s2LAvl_Val: accessed-variable=AcsEntry4s2LAvl.Val
            SEND_AcsEntry4s2RAvl_Val: accessed-variable=AcsEntry4s2RAvl.Val
            SEND_AcsEntryAll4sBwdAvl_Val: accessed-variable=AcsEntryAll4sBwdAvl.Val
            SEND_AcsEntryAll4sFwdAvl_Val: accessed-variable=AcsEntryAll4sFwdAvl.Val
            SEND_AcsExit4s2LAvl_Val: accessed-variable=AcsExit4s2LAvl.Val
            SEND_AcsExit4s2RAvl_Val: accessed-variable=AcsExit4s2RAvl.Val
            SEND_AcsMdEntyAvl_Val: accessed-variable=AcsMdEntyAvl.Val
            SEND_AcsMdExtAvl_Val: accessed-variable=AcsMdExtAvl.Val
            SEND_Big4SeatAvl_Val: accessed-variable=Big4SeatAvl.Val
            SEND_CommCond_Val: accessed-variable=CommCond.Val
            SEND_CommExitCond_Val: accessed-variable=CommExitCond.Val
            SEND_CommExitCondwithSpeed_Val: accessed-variable=CommExitCondwithSpeed.Val
            SEND_DiagAbgDly_Val: accessed-variable=DiagAbgDly.Val
            SEND_DiagVehMovState_Val: accessed-variable=DiagVehMovState.Val
            SEND_DiagVehSpdAvgDrvn_Val: accessed-variable=DiagVehSpdAvgDrvn.Val
            SEND_FamilyMdLtAvl_Val: accessed-variable=FamilyMdLtAvl.Val
            SEND_FamilyMdRtAvl_Val: accessed-variable=FamilyMdRtAvl.Val
            SEND_HMIMd10Avl_2L_Val: accessed-variable=HMIMd10Avl_2L.Val
            SEND_HMIMd10Avl_2R_Val: accessed-variable=HMIMd10Avl_2R.Val
            SEND_HMIMd10Cfg_2L_Val: accessed-variable=HMIMd10Cfg_2L.Val
            SEND_HMIMd10Cfg_2R_Val_1: accessed-variable=HMIMd10Cfg_2R.Val
            SEND_HMIMd11Avl_2L_Val: accessed-variable=HMIMd11Avl_2L.Val
            SEND_HMIMd11Avl_2R_Val: accessed-variable=HMIMd11Avl_2R.Val
            SEND_HMIMd11Cfg_2L_Val: accessed-variable=HMIMd11Cfg_2L.Val
            SEND_HMIMd11Cfg_2R_Val_1: accessed-variable=HMIMd11Cfg_2R.Val
            SEND_HMIMd12Avl_2L_Val: accessed-variable=HMIMd12Avl_2L.Val
            SEND_HMIMd12Avl_2R_Val: accessed-variable=HMIMd12Avl_2R.Val
            SEND_HMIMd12Cfg_2L_Val: accessed-variable=HMIMd12Cfg_2L.Val
            SEND_HMIMd12Cfg_2R_Val_1: accessed-variable=HMIMd12Cfg_2R.Val
            SEND_HMIMd13Avl_2L_Val: accessed-variable=HMIMd13Avl_2L.Val
            SEND_HMIMd13Avl_2R_Val: accessed-variable=HMIMd13Avl_2R.Val
            SEND_HMIMd13Cfg_2L_Val: accessed-variable=HMIMd13Cfg_2L.Val
            SEND_HMIMd13Cfg_2R_Val_1: accessed-variable=HMIMd13Cfg_2R.Val
            SEND_HMIMd14Avl_2L_Val: accessed-variable=HMIMd14Avl_2L.Val
            SEND_HMIMd14Avl_2R_Val: accessed-variable=HMIMd14Avl_2R.Val
            SEND_HMIMd14Cfg_2L_Val: accessed-variable=HMIMd14Cfg_2L.Val
            SEND_HMIMd14Cfg_2R_Val_1: accessed-variable=HMIMd14Cfg_2R.Val
            SEND_HMIMd15Avl_2L_Val: accessed-variable=HMIMd15Avl_2L.Val
            SEND_HMIMd15Avl_2R_Val: accessed-variable=HMIMd15Avl_2R.Val
            SEND_HMIMd15Cfg_2L_Val: accessed-variable=HMIMd15Cfg_2L.Val
            SEND_HMIMd15Cfg_2R_Val_1: accessed-variable=HMIMd15Cfg_2R.Val
            SEND_HMIMd16Avl_2L_Val: accessed-variable=HMIMd16Avl_2L.Val
            SEND_HMIMd16Avl_2R_Val: accessed-variable=HMIMd16Avl_2R.Val
            SEND_HMIMd16Cfg_2L_Val: accessed-variable=HMIMd16Cfg_2L.Val
            SEND_HMIMd16Cfg_2R_Val_1: accessed-variable=HMIMd16Cfg_2R.Val
            SEND_HMIMd17Avl_2L_Val: accessed-variable=HMIMd17Avl_2L.Val
            SEND_HMIMd17Avl_2R_Val: accessed-variable=HMIMd17Avl_2R.Val
            SEND_HMIMd17Cfg_2L_Val: accessed-variable=HMIMd17Cfg_2L.Val
            SEND_HMIMd17Cfg_2R_Val_1: accessed-variable=HMIMd17Cfg_2R.Val
            SEND_HMIMd18Avl_2L_Val: accessed-variable=HMIMd18Avl_2L.Val
            SEND_HMIMd18Avl_2R_Val: accessed-variable=HMIMd18Avl_2R.Val
            SEND_HMIMd18Cfg_2L_Val: accessed-variable=HMIMd18Cfg_2L.Val
            SEND_HMIMd18Cfg_2R_Val_1: accessed-variable=HMIMd18Cfg_2R.Val
            SEND_HMIMd19Avl_2L_Val: accessed-variable=HMIMd19Avl_2L.Val
            SEND_HMIMd19Avl_2R_Val: accessed-variable=HMIMd19Avl_2R.Val
            SEND_HMIMd19Cfg_2L_Val: accessed-variable=HMIMd19Cfg_2L.Val
            SEND_HMIMd19Cfg_2R_Val_1: accessed-variable=HMIMd19Cfg_2R.Val
            SEND_HMIMd1Avl_2L_Val: accessed-variable=HMIMd1Avl_2L.Val
            SEND_HMIMd1Avl_2R_Val: accessed-variable=HMIMd1Avl_2R.Val
            SEND_HMIMd1Cfg_2L_Val: accessed-variable=HMIMd1Cfg_2L.Val
            SEND_HMIMd1Cfg_2R_Val_1: accessed-variable=HMIMd1Cfg_2R.Val
            SEND_HMIMd20Avl_2L_Val: accessed-variable=HMIMd20Avl_2L.Val
            SEND_HMIMd20Avl_2R_Val: accessed-variable=HMIMd20Avl_2R.Val
            SEND_HMIMd20Cfg_2L_Val: accessed-variable=HMIMd20Cfg_2L.Val
            SEND_HMIMd20Cfg_2R_Val_1: accessed-variable=HMIMd20Cfg_2R.Val
            SEND_HMIMd21Avl_2L_Val: accessed-variable=HMIMd21Avl_2L.Val
            SEND_HMIMd21Avl_2R_Val: accessed-variable=HMIMd21Avl_2R.Val
            SEND_HMIMd21Cfg_2L_Val: accessed-variable=HMIMd21Cfg_2L.Val
            SEND_HMIMd21Cfg_2R_Val_1: accessed-variable=HMIMd21Cfg_2R.Val
            SEND_HMIMd22Avl_2L_Val: accessed-variable=HMIMd22Avl_2L.Val
            SEND_HMIMd22Avl_2R_Val: accessed-variable=HMIMd22Avl_2R.Val
            SEND_HMIMd22Cfg_2L_Val: accessed-variable=HMIMd22Cfg_2L.Val
            SEND_HMIMd22Cfg_2R_Val_1: accessed-variable=HMIMd22Cfg_2R.Val
            SEND_HMIMd23Avl_2L_Val: accessed-variable=HMIMd23Avl_2L.Val
            SEND_HMIMd23Avl_2R_Val: accessed-variable=HMIMd23Avl_2R.Val
            SEND_HMIMd23Cfg_2L_Val: accessed-variable=HMIMd23Cfg_2L.Val
            SEND_HMIMd23Cfg_2R_Val_1: accessed-variable=HMIMd23Cfg_2R.Val
            SEND_HMIMd24Avl_2L_Val: accessed-variable=HMIMd24Avl_2L.Val
            SEND_HMIMd24Avl_2R_Val: accessed-variable=HMIMd24Avl_2R.Val
            SEND_HMIMd24Cfg_2L_Val: accessed-variable=HMIMd24Cfg_2L.Val
            SEND_HMIMd24Cfg_2R_Val_1: accessed-variable=HMIMd24Cfg_2R.Val
            SEND_HMIMd25Avl_2L_Val: accessed-variable=HMIMd25Avl_2L.Val
            SEND_HMIMd25Avl_2R_Val: accessed-variable=HMIMd25Avl_2R.Val
            SEND_HMIMd25Cfg_2L_Val: accessed-variable=HMIMd25Cfg_2L.Val
            SEND_HMIMd25Cfg_2R_Val_1: accessed-variable=HMIMd25Cfg_2R.Val
            SEND_HMIMd26Avl_2L_Val: accessed-variable=HMIMd26Avl_2L.Val
            SEND_HMIMd26Avl_2R_Val: accessed-variable=HMIMd26Avl_2R.Val
            SEND_HMIMd26Cfg_2L_Val: accessed-variable=HMIMd26Cfg_2L.Val
            SEND_HMIMd26Cfg_2R_Val_1: accessed-variable=HMIMd26Cfg_2R.Val
            SEND_HMIMd27Avl_2L_Val: accessed-variable=HMIMd27Avl_2L.Val
            SEND_HMIMd27Avl_2R_Val: accessed-variable=HMIMd27Avl_2R.Val
            SEND_HMIMd27Cfg_2L_Val: accessed-variable=HMIMd27Cfg_2L.Val
            SEND_HMIMd27Cfg_2R_Val_1: accessed-variable=HMIMd27Cfg_2R.Val
            SEND_HMIMd28Avl_2L_Val: accessed-variable=HMIMd28Avl_2L.Val
            SEND_HMIMd28Avl_2R_Val: accessed-variable=HMIMd28Avl_2R.Val
            SEND_HMIMd28Cfg_2L_Val: accessed-variable=HMIMd28Cfg_2L.Val
            SEND_HMIMd28Cfg_2R_Val_1: accessed-variable=HMIMd28Cfg_2R.Val
            SEND_HMIMd29Avl_2L_Val: accessed-variable=HMIMd29Avl_2L.Val
            SEND_HMIMd29Avl_2R_Val: accessed-variable=HMIMd29Avl_2R.Val
            SEND_HMIMd29Cfg_2L_Val: accessed-variable=HMIMd29Cfg_2L.Val
            SEND_HMIMd29Cfg_2R_Val_1: accessed-variable=HMIMd29Cfg_2R.Val
            SEND_HMIMd2Avl_2L_Val: accessed-variable=HMIMd2Avl_2L.Val
            SEND_HMIMd2Avl_2R_Val: accessed-variable=HMIMd2Avl_2R.Val
            SEND_HMIMd2Cfg_2L_Val: accessed-variable=HMIMd2Cfg_2L.Val
            SEND_HMIMd2Cfg_2R_Val_1: accessed-variable=HMIMd2Cfg_2R.Val
            SEND_HMIMd30Avl_2L_Val: accessed-variable=HMIMd30Avl_2L.Val
            SEND_HMIMd30Avl_2R_Val: accessed-variable=HMIMd30Avl_2R.Val
            SEND_HMIMd30Cfg_2L_Val: accessed-variable=HMIMd30Cfg_2L.Val
            SEND_HMIMd30Cfg_2R_Val_1: accessed-variable=HMIMd30Cfg_2R.Val
            SEND_HMIMd31Avl_2L_Val: accessed-variable=HMIMd31Avl_2L.Val
            SEND_HMIMd31Avl_2R_Val: accessed-variable=HMIMd31Avl_2R.Val
            SEND_HMIMd31Cfg_2L_Val: accessed-variable=HMIMd31Cfg_2L.Val
            SEND_HMIMd31Cfg_2R_Val_1: accessed-variable=HMIMd31Cfg_2R.Val
            SEND_HMIMd32Avl_2L_Val: accessed-variable=HMIMd32Avl_2L.Val
            SEND_HMIMd32Avl_2R_Val: accessed-variable=HMIMd32Avl_2R.Val
            SEND_HMIMd32Cfg_2L_Val: accessed-variable=HMIMd32Cfg_2L.Val
            SEND_HMIMd32Cfg_2R_Val_1: accessed-variable=HMIMd32Cfg_2R.Val
            SEND_HMIMd3Avl_2L_Val: accessed-variable=HMIMd3Avl_2L.Val
            SEND_HMIMd3Avl_2R_Val: accessed-variable=HMIMd3Avl_2R.Val
            SEND_HMIMd3Cfg_2L_Val: accessed-variable=HMIMd3Cfg_2L.Val
            SEND_HMIMd3Cfg_2R_Val_1: accessed-variable=HMIMd3Cfg_2R.Val
            SEND_HMIMd4Avl_2L_Val: accessed-variable=HMIMd4Avl_2L.Val
            SEND_HMIMd4Avl_2R_Val: accessed-variable=HMIMd4Avl_2R.Val
            SEND_HMIMd4Cfg_2L_Val: accessed-variable=HMIMd4Cfg_2L.Val
            SEND_HMIMd4Cfg_2R_Val_1: accessed-variable=HMIMd4Cfg_2R.Val
            SEND_HMIMd5Avl_2L_Val: accessed-variable=HMIMd5Avl_2L.Val
            SEND_HMIMd5Avl_2R_Val: accessed-variable=HMIMd5Avl_2R.Val
            SEND_HMIMd5Cfg_2L_Val: accessed-variable=HMIMd5Cfg_2L.Val
            SEND_HMIMd5Cfg_2R_Val_1: accessed-variable=HMIMd5Cfg_2R.Val
            SEND_HMIMd6Avl_2L_Val: accessed-variable=HMIMd6Avl_2L.Val
            SEND_HMIMd6Avl_2R_Val: accessed-variable=HMIMd6Avl_2R.Val
            SEND_HMIMd6Cfg_2L_Val: accessed-variable=HMIMd6Cfg_2L.Val
            SEND_HMIMd6Cfg_2R_Val_1: accessed-variable=HMIMd6Cfg_2R.Val
            SEND_HMIMd7Avl_2L_Val: accessed-variable=HMIMd7Avl_2L.Val
            SEND_HMIMd7Avl_2R_Val: accessed-variable=HMIMd7Avl_2R.Val
            SEND_HMIMd7Cfg_2L_Val: accessed-variable=HMIMd7Cfg_2L.Val
            SEND_HMIMd7Cfg_2R_Val_1: accessed-variable=HMIMd7Cfg_2R.Val
            SEND_HMIMd8Avl_2L_Val: accessed-variable=HMIMd8Avl_2L.Val
            SEND_HMIMd8Avl_2R_Val: accessed-variable=HMIMd8Avl_2R.Val
            SEND_HMIMd8Cfg_2L_Val: accessed-variable=HMIMd8Cfg_2L.Val
            SEND_HMIMd8Cfg_2R_Val_1: accessed-variable=HMIMd8Cfg_2R.Val
            SEND_HMIMd9Avl_2L_Val: accessed-variable=HMIMd9Avl_2L.Val
            SEND_HMIMd9Avl_2R_Val: accessed-variable=HMIMd9Avl_2R.Val
            SEND_HMIMd9Cfg_2L_Val: accessed-variable=HMIMd9Cfg_2L.Val
            SEND_HMIMd9Cfg_2R_Val_1: accessed-variable=HMIMd9Cfg_2R.Val
            SEND_IntimacyMdAvl_Val: accessed-variable=IntimacyLMdAvl.Val
            SEND_IntimacyRMdAvl_Val: accessed-variable=IntimacyRMdAvl.Val
            SEND_LgrstCloseLtAvl_Val: accessed-variable=LgrstCloseLtMdAvl.Val
            SEND_LgrstCloseRtAvl_Val: accessed-variable=LgrstCloseRtMdAvl.Val
            SEND_LgrstOpenLtAvl_Val: accessed-variable=LgrstOpenLtMdAvl.Val
            SEND_LgrstOpenRtAvl_Val: accessed-variable=LgrstOpenRtMdAvl.Val
            SEND_LugMdLtAvl_Val: accessed-variable=LugMdLtAvl.Val
            SEND_LugMdRtAvl_Val: accessed-variable=LugMdRtAvl.Val
            SEND_LyingMdLtAvl_Val: accessed-variable=LyingMdLtAvl.Val
            SEND_LyingMdRtAvl_Val: accessed-variable=LyingMdRtAvl.Val
            SEND_M61WholeVehMemAvl_Val: accessed-variable=M61WholeVehMemAvl.Val
            SEND_M62WholeVehMemAvl_Val: accessed-variable=M62WholeVehMemAvl.Val
            SEND_PasReclinerAvl_Val: accessed-variable=PasReclinerAvl.Val
            SEND_PasReclinerExitAvl_Val: accessed-variable=PasReclinerExitAvl.Val
            SEND_PwrMdChked_Val: accessed-variable=PwrMdChked.Val
            SEND_RcvyMdLtAvl_Val: accessed-variable=RcvyMdLtAvl.Val
            SEND_RcvyMdRtAvl_Val: accessed-variable=RcvyMdRtAvl.Val
            SEND_StPassCmprtMdCtrl_Md1_VCUAvl_Val: accessed-variable=StPassCmprtMdCtrl_Md1_VCUAvl.Val
            SEND_StPassCmprtMdCtrl_Md1_VCUCfg_Val: accessed-variable=StPassCmprtMdCtrl_Md1_VCUCfg.Val
            SEND_StPassCmprtMdCtrl_Md10_VCUAvl_Val: accessed-variable=StPassCmprtMdCtrl_Md10_VCUAvl.Val
            SEND_StPassCmprtMdCtrl_Md10_VCUCfg_Val: accessed-variable=StPassCmprtMdCtrl_Md10_VCUCfg.Val
            SEND_StPassCmprtMdCtrl_Md11_VCUAvl_Val: accessed-variable=StPassCmprtMdCtrl_Md11_VCUAvl.Val
            SEND_StPassCmprtMdCtrl_Md11_VCUCfg_Val: accessed-variable=StPassCmprtMdCtrl_Md11_VCUCfg.Val
            SEND_StPassCmprtMdCtrl_Md12_VCUAvl_Val: accessed-variable=StPassCmprtMdCtrl_Md12_VCUAvl.Val
            SEND_StPassCmprtMdCtrl_Md12_VCUCfg_Val: accessed-variable=StPassCmprtMdCtrl_Md12_VCUCfg.Val
            SEND_StPassCmprtMdCtrl_Md13_VCUAvl_Val: accessed-variable=StPassCmprtMdCtrl_Md13_VCUAvl.Val
            SEND_StPassCmprtMdCtrl_Md13_VCUCfg_Val: accessed-variable=StPassCmprtMdCtrl_Md13_VCUCfg.Val
            SEND_StPassCmprtMdCtrl_Md14_VCUAvl_Val: accessed-variable=StPassCmprtMdCtrl_Md14_VCUAvl.Val
            SEND_StPassCmprtMdCtrl_Md14_VCUCfg_Val: accessed-variable=StPassCmprtMdCtrl_Md14_VCUCfg.Val
            SEND_StPassCmprtMdCtrl_Md15_VCUAvl_Val: accessed-variable=StPassCmprtMdCtrl_Md15_VCUAvl.Val
            SEND_StPassCmprtMdCtrl_Md15_VCUCfg_Val: accessed-variable=StPassCmprtMdCtrl_Md15_VCUCfg.Val
            SEND_StPassCmprtMdCtrl_Md16_VCUAvl_Val: accessed-variable=StPassCmprtMdCtrl_Md16_VCUAvl.Val
            SEND_StPassCmprtMdCtrl_Md16_VCUCfg_Val: accessed-variable=StPassCmprtMdCtrl_Md16_VCUCfg.Val
            SEND_StPassCmprtMdCtrl_Md17_VCUAvl_Val: accessed-variable=StPassCmprtMdCtrl_Md17_VCUAvl.Val
            SEND_StPassCmprtMdCtrl_Md17_VCUCfg_Val: accessed-variable=StPassCmprtMdCtrl_Md17_VCUCfg.Val
            SEND_StPassCmprtMdCtrl_Md18_VCUAvl_Val: accessed-variable=StPassCmprtMdCtrl_Md18_VCUAvl.Val
            SEND_StPassCmprtMdCtrl_Md18_VCUCfg_Val: accessed-variable=StPassCmprtMdCtrl_Md18_VCUCfg.Val
            SEND_StPassCmprtMdCtrl_Md19_VCUAvl_Val: accessed-variable=StPassCmprtMdCtrl_Md19_VCUAvl.Val
            SEND_StPassCmprtMdCtrl_Md19_VCUCfg_Val: accessed-variable=StPassCmprtMdCtrl_Md19_VCUCfg.Val
            SEND_StPassCmprtMdCtrl_Md2_VCUAvl_Val: accessed-variable=StPassCmprtMdCtrl_Md2_VCUAvl.Val
            SEND_StPassCmprtMdCtrl_Md2_VCUCfg_Val: accessed-variable=StPassCmprtMdCtrl_Md2_VCUCfg.Val
            SEND_StPassCmprtMdCtrl_Md20_VCUAvl_Val: accessed-variable=StPassCmprtMdCtrl_Md20_VCUAvl.Val
            SEND_StPassCmprtMdCtrl_Md20_VCUCfg_Val: accessed-variable=StPassCmprtMdCtrl_Md20_VCUCfg.Val
            SEND_StPassCmprtMdCtrl_Md21_VCUAvl_Val: accessed-variable=StPassCmprtMdCtrl_Md21_VCUAvl.Val
            SEND_StPassCmprtMdCtrl_Md21_VCUCfg_Val: accessed-variable=StPassCmprtMdCtrl_Md21_VCUCfg.Val
            SEND_StPassCmprtMdCtrl_Md22_VCUAvl_Val: accessed-variable=StPassCmprtMdCtrl_Md22_VCUAvl.Val
            SEND_StPassCmprtMdCtrl_Md22_VCUCfg_Val: accessed-variable=StPassCmprtMdCtrl_Md22_VCUCfg.Val
            SEND_StPassCmprtMdCtrl_Md23_VCUAvl_Val: accessed-variable=StPassCmprtMdCtrl_Md23_VCUAvl.Val
            SEND_StPassCmprtMdCtrl_Md23_VCUCfg_Val: accessed-variable=StPassCmprtMdCtrl_Md23_VCUCfg.Val
            SEND_StPassCmprtMdCtrl_Md24_VCUAvl_Val: accessed-variable=StPassCmprtMdCtrl_Md24_VCUAvl.Val
            SEND_StPassCmprtMdCtrl_Md24_VCUCfg_Val: accessed-variable=StPassCmprtMdCtrl_Md24_VCUCfg.Val
            SEND_StPassCmprtMdCtrl_Md25_VCUAvl_Val: accessed-variable=StPassCmprtMdCtrl_Md25_VCUAvl.Val
            SEND_StPassCmprtMdCtrl_Md25_VCUCfg_Val: accessed-variable=StPassCmprtMdCtrl_Md25_VCUCfg.Val
            SEND_StPassCmprtMdCtrl_Md26_VCUAvl_Val: accessed-variable=StPassCmprtMdCtrl_Md26_VCUAvl.Val
            SEND_StPassCmprtMdCtrl_Md26_VCUCfg_Val: accessed-variable=StPassCmprtMdCtrl_Md26_VCUCfg.Val
            SEND_StPassCmprtMdCtrl_Md27_VCUAvl_Val: accessed-variable=StPassCmprtMdCtrl_Md27_VCUAvl.Val
            SEND_StPassCmprtMdCtrl_Md27_VCUCfg_Val: accessed-variable=StPassCmprtMdCtrl_Md27_VCUCfg.Val
            SEND_StPassCmprtMdCtrl_Md28_VCUAvl_Val: accessed-variable=StPassCmprtMdCtrl_Md28_VCUAvl.Val
            SEND_StPassCmprtMdCtrl_Md28_VCUCfg_Val: accessed-variable=StPassCmprtMdCtrl_Md28_VCUCfg.Val
            SEND_StPassCmprtMdCtrl_Md29_VCUAvl_Val: accessed-variable=StPassCmprtMdCtrl_Md29_VCUAvl.Val
            SEND_StPassCmprtMdCtrl_Md29_VCUCfg_Val: accessed-variable=StPassCmprtMdCtrl_Md29_VCUCfg.Val
            SEND_StPassCmprtMdCtrl_Md3_VCUAvl_Val: accessed-variable=StPassCmprtMdCtrl_Md3_VCUAvl.Val
            SEND_StPassCmprtMdCtrl_Md3_VCUCfg_Val: accessed-variable=StPassCmprtMdCtrl_Md3_VCUCfg.Val
            SEND_StPassCmprtMdCtrl_Md30_VCUAvl_Val: accessed-variable=StPassCmprtMdCtrl_Md30_VCUAvl.Val
            SEND_StPassCmprtMdCtrl_Md30_VCUCfg_Val: accessed-variable=StPassCmprtMdCtrl_Md30_VCUCfg.Val
            SEND_StPassCmprtMdCtrl_Md31_VCUAvl_Val: accessed-variable=StPassCmprtMdCtrl_Md31_VCUAvl.Val
            SEND_StPassCmprtMdCtrl_Md31_VCUCfg_Val: accessed-variable=StPassCmprtMdCtrl_Md31_VCUCfg.Val
            SEND_StPassCmprtMdCtrl_Md32_VCUAvl_Val: accessed-variable=StPassCmprtMdCtrl_Md32_VCUAvl.Val
            SEND_StPassCmprtMdCtrl_Md32_VCUCfg_Val: accessed-variable=StPassCmprtMdCtrl_Md32_VCUCfg.Val
            SEND_StPassCmprtMdCtrl_Md4_VCUAvl_Val: accessed-variable=StPassCmprtMdCtrl_Md4_VCUAvl.Val
            SEND_StPassCmprtMdCtrl_Md4_VCUCfg_Val: accessed-variable=StPassCmprtMdCtrl_Md4_VCUCfg.Val
            SEND_StPassCmprtMdCtrl_Md5_VCUAvl_Val: accessed-variable=StPassCmprtMdCtrl_Md5_VCUAvl.Val
            SEND_StPassCmprtMdCtrl_Md5_VCUCfg_Val: accessed-variable=StPassCmprtMdCtrl_Md5_VCUCfg.Val
            SEND_StPassCmprtMdCtrl_Md53_VCUAvl_Val: accessed-variable=StPassCmprtMdCtrl_Md53_VCUAvl.Val
            SEND_StPassCmprtMdCtrl_Md53_VCUCfg_Val: accessed-variable=StPassCmprtMdCtrl_Md53_VCUCfg.Val
            SEND_StPassCmprtMdCtrl_Md56_VCUAvl_Val: accessed-variable=StPassCmprtMdCtrl_Md56_VCUAvl.Val
            SEND_StPassCmprtMdCtrl_Md56_VCUCfg_Val: accessed-variable=StPassCmprtMdCtrl_Md56_VCUCfg.Val
            SEND_StPassCmprtMdCtrl_Md57_VCUAvl_Val: accessed-variable=StPassCmprtMdCtrl_Md57_VCUAvl.Val
            SEND_StPassCmprtMdCtrl_Md57_VCUCfg_Val: accessed-variable=StPassCmprtMdCtrl_Md57_VCUCfg.Val
            SEND_StPassCmprtMdCtrl_Md58_VCUAvl_Val: accessed-variable=StPassCmprtMdCtrl_Md58_VCUAvl.Val
            SEND_StPassCmprtMdCtrl_Md58_VCUCfg_Val: accessed-variable=StPassCmprtMdCtrl_Md58_VCUCfg.Val
            SEND_StPassCmprtMdCtrl_Md6_VCUAvl_Val: accessed-variable=StPassCmprtMdCtrl_Md6_VCUAvl.Val
            SEND_StPassCmprtMdCtrl_Md6_VCUCfg_Val: accessed-variable=StPassCmprtMdCtrl_Md6_VCUCfg.Val
            SEND_StPassCmprtMdCtrl_Md61_VCUAvl_Val: accessed-variable=StPassCmprtMdCtrl_Md61_VCUAvl.Val
            SEND_StPassCmprtMdCtrl_Md61_VCUCfg_Val: accessed-variable=StPassCmprtMdCtrl_Md61_VCUCfg.Val
            SEND_StPassCmprtMdCtrl_Md62_VCUAvl_Val: accessed-variable=StPassCmprtMdCtrl_Md62_VCUAvl.Val
            SEND_StPassCmprtMdCtrl_Md62_VCUCfg_Val: accessed-variable=StPassCmprtMdCtrl_Md62_VCUCfg.Val
            SEND_StPassCmprtMdCtrl_Md7_VCUAvl_Val: accessed-variable=StPassCmprtMdCtrl_Md7_VCUAvl.Val
            SEND_StPassCmprtMdCtrl_Md7_VCUCfg_Val: accessed-variable=StPassCmprtMdCtrl_Md7_VCUCfg.Val
            SEND_StPassCmprtMdCtrl_Md8_VCUAvl_Val: accessed-variable=StPassCmprtMdCtrl_Md8_VCUAvl.Val
            SEND_StPassCmprtMdCtrl_Md8_VCUCfg_Val: accessed-variable=StPassCmprtMdCtrl_Md8_VCUCfg.Val
            SEND_StPassCmprtMdCtrl_Md9_VCUAvl_Val: accessed-variable=StPassCmprtMdCtrl_Md9_VCUAvl.Val
            SEND_StPassCmprtMdCtrl_Md9_VCUCfg_Val: accessed-variable=StPassCmprtMdCtrl_Md9_VCUCfg.Val
            SEND_StPassCmprtMdRfCtrlSwCstStAvl_Val: accessed-variable=StPassCmprtMdRfCtrlSwCstStAvl.Val
            SEND_StSrvAvl_Md1_Val: accessed-variable=StSrvAvl_Md1.Val
            SEND_StSrvAvl_Md{10..19}_Val: accessed-variable=StSrvAvl_Md{10..19}.Val
            SEND_StSrvAvl_Md2_Val: accessed-variable=StSrvAvl_Md2.Val
            SEND_StSrvAvl_Md{20..29}_Val: accessed-variable=StSrvAvl_Md{20..29}.Val
            SEND_StSrvAvl_Md3_Val: accessed-variable=StSrvAvl_Md3.Val
            SEND_StSrvAvl_Md{30..32}_Val: accessed-variable=StSrvAvl_Md{30..32}.Val
            SEND_StSrvAvl_Md{4..9}_Val: accessed-variable=StSrvAvl_Md{4..9}.Val
            SEND_StSrvCfg_Md1_Val: accessed-variable=StSrvCfg_Md1.Val
            SEND_StSrvCfg_Md{10..19}_Val: accessed-variable=StSrvCfg_Md{10..19}.Val
            SEND_StSrvCfg_Md2_Val: accessed-variable=StSrvCfg_Md2.Val
            SEND_StSrvCfg_Md{20..29}_Val: accessed-variable=StSrvCfg_Md{20..29}.Val
            SEND_StSrvCfg_Md3_Val: accessed-variable=StSrvCfg_Md3.Val
            SEND_StSrvCfg_Md{30..32}_Val: accessed-variable=StSrvCfg_Md{30..32}.Val
            SEND_StSrvCfg_Md{4..9}_Val: accessed-variable=StSrvCfg_Md{4..9}.Val
            SEND_unfold3LAvl_Val: accessed-variable=unfold3LAvl.Val
            SEND_unfold3RAvl_Val: accessed-variable=unfold3RAvl.Val
            SEND_VipLtOutMdAvl_Val: accessed-variable=VipLtOutMdAvl.Val
            SEND_VipMdLtAvl_Val: accessed-variable=VipMdLtAvl.Val
            SEND_VipMdRtAvl_Val: accessed-variable=VipMdRtAvl.Val
            SEND_VipRtOutMdAvl_Val: accessed-variable=VipRtOutMdAvl.Val
        146 x parameter access:
          PA_HMI_2L_StMd1_Config_Val: accessed-parameter=HMI_2L_StMd1_Config.Val
          PA_HMI_2L_StMd{10..19}_Config_Val: accessed-parameter=HMI_2L_StMd{10..19}_Config.Val
          PA_HMI_2L_StMd2_Config_Val: accessed-parameter=HMI_2L_StMd2_Config.Val
          PA_HMI_2L_StMd{20..29}_Config_Val: accessed-parameter=HMI_2L_StMd{20..29}_Config.Val
          PA_HMI_2L_StMd3_Config_Val: accessed-parameter=HMI_2L_StMd3_Config.Val
          PA_HMI_2L_StMd{30..32}_Config_Val: accessed-parameter=HMI_2L_StMd{30..32}_Config.Val
          PA_HMI_2L_StMd{4..9}_Config_Val: accessed-parameter=HMI_2L_StMd{4..9}_Config.Val
          PA_HMI_2R_StMd1_Config_Val: accessed-parameter=HMI_2R_StMd1_Config.Val
          PA_HMI_2R_StMd{10..19}_Config_Val: accessed-parameter=HMI_2R_StMd{10..19}_Config.Val
          PA_HMI_2R_StMd2_Config_Val: accessed-parameter=HMI_2R_StMd2_Config.Val
          PA_HMI_2R_StMd{20..29}_Config_Val: accessed-parameter=HMI_2R_StMd{20..29}_Config.Val
          PA_HMI_2R_StMd3_Config_Val: accessed-parameter=HMI_2R_StMd3_Config.Val
          PA_HMI_2R_StMd{30..32}_Config_Val: accessed-parameter=HMI_2R_StMd{30..32}_Config.Val
          PA_HMI_2R_StMd{4..9}_Config_Val: accessed-parameter=HMI_2R_StMd{4..9}_Config.Val
          PA_IfKeSMSbSeatMovFrwdBkwdEnable_Val: accessed-parameter=IfKeSMSbSeatMovFrwdBkwdEnable.Val
          PA_KeSMSbRoofSWEnable_Val: accessed-parameter=KeSMSbRoofSWEnable.Val
          PA_KeSMSLegrstDisFwdBkwdPos_Val: accessed-parameter=KeSMSLegrstDisFwdBkwdPos.Val
          PA_KeSMSuSecRwStBackPosDelta_Val: accessed-parameter=KeSMSuSecRwStBackPosDelta.Val
          PA_KeSMSuThrdRwCushFoldPosDelta_Val: accessed-parameter=KeSMSuThrdRwCushFoldPosDelta.Val
          PA_KeSMSuThrdRwCushFoldPosThreshold_Val: accessed-parameter=KeSMSuThrdRwCushFoldPosThreshold.Val
          PA_KeSMSwAcsMd32SecRwLtStBkReclnUpwdDnwdPos1_Val: accessed-parameter=KeSMSwAcsMd32SecRwLtStBkReclnUpwdDnwdPos1.Val
          PA_KeSMSwAcsMd53SecRwRtStBkReclnUpwdDnwdPos1_Val: accessed-parameter=KeSMSwAcsMd53SecRwRtStBkReclnUpwdDnwdPos1.Val
          PA_KeSMSwAcsMd8SecRwLtStBkReclnUpwdDnwdPos_Val: accessed-parameter=KeSMSwAcsMd8SecRwLtStBkReclnUpwdDnwdPos.Val
          PA_KeSMSwAcsMd9SecRwRtStBkReclnUpwdDnwdPos_Val: accessed-parameter=KeSMSwAcsMd9SecRwRtStBkReclnUpwdDnwdPos.Val
          PA_KeSMSwSeatBkLimitPos_Val: accessed-parameter=KeSMSwSeatBkLimitPos.Val
          PA_KeSMSwSeatBkLimitPosDelt_Val: accessed-parameter=KeSMSwSeatBkLimitPosDelt.Val
          PA_StPassCmprtMdCtrl_Md1_VCUConfig_Val: accessed-parameter=StPassCmprtMdCtrl_Md1_VCUConfig.Val
          PA_StPassCmprtMdCtrl_Md{10..19}_VCUConfig_Val: accessed-parameter=StPassCmprtMdCtrl_Md{10..19}_VCUConfig.Val
          PA_StPassCmprtMdCtrl_Md2_VCUConfig_Val: accessed-parameter=StPassCmprtMdCtrl_Md2_VCUConfig.Val
          PA_StPassCmprtMdCtrl_Md{20..29}_VCUConfig_Val: accessed-parameter=StPassCmprtMdCtrl_Md{20..29}_VCUConfig.Val
          PA_StPassCmprtMdCtrl_Md3_VCUConfig_Val: accessed-parameter=StPassCmprtMdCtrl_Md3_VCUConfig.Val
          PA_StPassCmprtMdCtrl_Md{30..32}_VCUConfig_Val: accessed-parameter=StPassCmprtMdCtrl_Md{30..32}_VCUConfig.Val
          PA_StPassCmprtMdCtrl_Md4_VCUConfig_Val: accessed-parameter=StPassCmprtMdCtrl_Md4_VCUConfig.Val
          PA_StPassCmprtMdCtrl_Md5_VCUConfig_Val: accessed-parameter=StPassCmprtMdCtrl_Md5_VCUConfig.Val
          PA_StPassCmprtMdCtrl_Md53_VCUConfig_Val: accessed-parameter=StPassCmprtMdCtrl_Md53_VCUConfig.Val
          PA_StPassCmprtMdCtrl_Md{56..58}_VCUConfig_Val: accessed-parameter=StPassCmprtMdCtrl_Md{56..58}_VCUConfig.Val
          PA_StPassCmprtMdCtrl_Md6_VCUConfig_Val: accessed-parameter=StPassCmprtMdCtrl_Md6_VCUConfig.Val
          PA_StPassCmprtMdCtrl_Md61_VCUConfig_Val: accessed-parameter=StPassCmprtMdCtrl_Md61_VCUConfig.Val
          PA_StPassCmprtMdCtrl_Md62_VCUConfig_Val: accessed-parameter=StPassCmprtMdCtrl_Md62_VCUConfig.Val
          PA_StPassCmprtMdCtrl_Md{7..9}_VCUConfig_Val: accessed-parameter=StPassCmprtMdCtrl_Md{7..9}_VCUConfig.Val
          PA_StSrv_StMd1_Config_Val: accessed-parameter=StSrv_StMd1_Config.Val
          PA_StSrv_StMd{10..19}_Config_Val: accessed-parameter=StSrv_StMd{10..19}_Config.Val
          PA_StSrv_StMd2_Config_Val: accessed-parameter=StSrv_StMd2_Config.Val
          PA_StSrv_StMd{20..29}_Config_Val: accessed-parameter=StSrv_StMd{20..29}_Config.Val
          PA_StSrv_StMd3_Config_Val: accessed-parameter=StSrv_StMd3_Config.Val
          PA_StSrv_StMd{30..32}_Config_Val: accessed-parameter=StSrv_StMd{30..32}_Config.Val
          PA_StSrv_StMd{4..9}_Config_Val: accessed-parameter=StSrv_StMd{4..9}_Config.Val
  swc implementation PreCondition_Implementation: behavior=PreCondition_InternalBehavior
    code-descriptors:
      code Default: artifact-descriptors=autosar-engineering-object={short-label=Default, category=SWSRC}
package /PATAC/MSM/ModeAdjust/CalPortInterface
  7 x parameter interface:
    KeSMSbHMICfg
      parameter data prototype Val: sw-calibration-access=READ-WRITE, type=Boolean
    KeSMSbStPassCmprtMdVCUCfg
      parameter data prototype Val: sw-calibration-access=READ-WRITE, type=Boolean
    KeSMSbStSrvCfg
      parameter data prototype Val: sw-calibration-access=READ-WRITE, type=Boolean
    KeSMSLegrstDisFwdBkwdPos
      parameter data prototype Val: sw-calibration-access=READ-WRITE, type=UInt16
    KeSMSwDltPos
      parameter data prototype Val: sw-calibration-access=READ-WRITE, type=UInt16
    MdPosDelta
      parameter data prototype Val: sw-calibration-access=READ-WRITE, type=UInt16
    Pos
      parameter data prototype Val: sw-calibration-access=READ-WRITE, type=UInt16
package /PATAC/MSM/ModeAdjust/DataType
  9 x impl type, all with category=VALUE, sw-calibration-access=READ-ONLY, type-emitter=RTE:
    DiagAbgDly: base-type=UInt8, compu {0=NoAbgDly, 1=AbgDly, 2=invalid}
    DiagVehMovState: base-type=UInt8, compu {0=Park, 1=NoPark, 2=invalid1}
    DiagVehSpdAvgDrvn: base-type=UInt8, compu {0=BelowTwo, 1=AboveTwo, 2=invalid2}
    EnergyMgLdShdRq1: base-type=UInt8, compu {0=EnergyMgLdShdRq_NoLdShd, 1..4=EnergyMgLdShdRq_LdShdLv1..EnergyMgLdShdRq_LdShdLv4}
    PosLrnd1: base-type=Boolean
    PosRclRspStat1: base-type=UInt8, compu {0=PosRclRspStat_None, 1=PosRclRspStat_RecallSuccessfully, 2=PosRclRspStat_RecallUnsuccessfully, 3=PosRclRspStat_RecallOngoing}
    PowerMode1: base-type=UInt8, compu {0=PowerMode_Off, 1=PowerMode_Acc, 2=PowerMode_Run, 3=PowerMode_Crank, 4=PowerMode_Invalid}
    SeatOccupiedSts1: base-type=UInt8, compu {0=SeatOccupiedSts_Unknown, 1=SeatOccupiedSts_Empty, 2=SeatOccupiedSts_Occupied, 3=SeatOccupiedSts_DataNotAvailable}
    VehMovState1: base-type=UInt8, compu {0=VehMvSts_Parked, 1=VehMvSts_Neutral, 2=VehMvSts_Forward, 3=VehMvSts_Reverse, 4=VehMvSts_Invalid}
package /PATAC/MSM/ModeAdjust/Interfaces
  6 x sender receiver interface:
    IfVeSMSeSecRwLtStChldLkReq: invalidation-policy{data-element=IfVeSMSeSecRwLtStChldLkReq/Val, handle-invalid=DONT-INVALIDATE}
      data Val: type=SeatChldLkSt
    IfVeSMSeSecRwRtStChldLkReq: invalidation-policy{data-element=IfVeSMSeSecRwRtStChldLkReq/Val, handle-invalid=DONT-INVALIDATE}
      data Val: type=SeatChldLkSt
    IfVeSMSuThdRwLtStCshnFldUpwdDnwdPos: invalidation-policy{data-element=IfVeSMSuThdRwLtStCshnFldUpwdDnwdPos/Val, handle-invalid=DONT-INVALIDATE}
      data Val: type=UInt16
    IfVeSMSuThdRwLtStCshnFldUpwdDnwdPosV: invalidation-policy{data-element=IfVeSMSuThdRwLtStCshnFldUpwdDnwdPosV/Val, handle-invalid=DONT-INVALIDATE}
      data Val: type=Boolean
    IfVeSMSuThdRwRtStCshnFldUpwdDnwdPos: invalidation-policy{data-element=IfVeSMSuThdRwRtStCshnFldUpwdDnwdPos/Val, handle-invalid=DONT-INVALIDATE}
      data Val: type=UInt16
    IfVeSMSuThdRwRtStCshnFldUpwdDnwdPosV: invalidation-policy{data-element=IfVeSMSuThdRwRtStCshnFldUpwdDnwdPosV/Val, handle-invalid=DONT-INVALIDATE}
      data Val: type=Boolean
package /PATAC/MSM/ModeAdjust/PortInterface
  29 x sender receiver interface:
    CommCond: invalidation-policy{data-element=CommCond/Val, handle-invalid=DONT-INVALIDATE}
      data Val: type=Boolean
    CommExitCond: invalidation-policy{data-element=CommExitCond/Val, handle-invalid=DONT-INVALIDATE}
      data Val: type=Boolean
    CommExitCondwithSpeed: invalidation-policy{data-element=CommExitCondwithSpeed/Val, handle-invalid=DONT-INVALIDATE}
      data Val: type=Boolean
    DiagAbgDly: invalidation-policy{data-element=DiagAbgDly/Val, handle-invalid=DONT-INVALIDATE}
      data Val: type=DiagAbgDly
    DiagVehMovState: invalidation-policy{data-element=DiagVehMovState/Val, handle-invalid=DONT-INVALIDATE}
      data Val: type=DiagVehMovState
    DiagVehSpdAvgDrvn: invalidation-policy{data-element=DiagVehSpdAvgDrvn/Val, handle-invalid=DONT-INVALIDATE}
      data Val: type=DiagVehSpdAvgDrvn
    EnergyMgLdShdRq: invalidation-policy{data-element=EnergyMgLdShdRq/Val, handle-invalid=DONT-INVALIDATE}
      data Val: type=EnergyMgLdShdRq1
    HMIAvl: invalidation-policy{data-element=HMIAvl/Val, handle-invalid=DONT-INVALIDATE}
      data Val: type=Boolean
    HMICfg: invalidation-policy{data-element=HMICfg/Val, handle-invalid=DONT-INVALIDATE}
      data Val: type=Boolean
    IfVeSMSbAbgDplyBckp: invalidation-policy{data-element=IfVeSMSbAbgDplyBckp/Val, handle-invalid=DONT-INVALIDATE}
      data Val: type=Boolean
    IfVeSMSeStNumConfig: invalidation-policy{data-element=IfVeSMSeStNumConfig/Val, handle-invalid=DONT-INVALIDATE}
      data Val: type=IfVeSMSeStNumConfig
    IfVeSMSeThdRwLtStChldLkReq: invalidation-policy{data-element=IfVeSMSeThdRwLtStChldLkReq/Val, handle-invalid=DONT-INVALIDATE}
      data Val: type=SeatChldLkSt
    IfVeSMSuMmryRclImpctDisRq: invalidation-policy{data-element=IfVeSMSuMmryRclImpctDisRq/Val, handle-invalid=DONT-INVALIDATE}
      data Val: type=UInt8
    ModeAdjustAvailable: invalidation-policy{data-element=ModeAdjustAvailable/Val, handle-invalid=DONT-INVALIDATE}
      data Val: type=Boolean
    PercPos: invalidation-policy{data-element=PercPos/Val, handle-invalid=DONT-INVALIDATE}
      data Val: type=UInt16
    PosAvail: invalidation-policy{data-element=PosAvail/Val, handle-invalid=DONT-INVALIDATE}
      data Val: type=Boolean
    PosLrnd: invalidation-policy{data-element=PosLrnd/Val, handle-invalid=DONT-INVALIDATE}
      data Val: type=PosLrnd1
    PosRclRspStat: invalidation-policy{data-element=PosRclRspStat/Val, handle-invalid=DONT-INVALIDATE}
      data Val: type=PosRclRspStat1
    PowerMode: invalidation-policy{data-element=PowerMode/Val, handle-invalid=DONT-INVALIDATE}
      data Val: type=PowerMode1
    SeatOccupiedState: invalidation-policy{data-element=SeatOccupiedState/Val, handle-invalid=DONT-INVALIDATE}
      data Val: type=SeatOccupiedSts1
    StPassCmprtMd_VCUCfg: invalidation-policy{data-element=StPassCmprtMd_VCUCfg/Val, handle-invalid=DONT-INVALIDATE}
      data Val: type=Boolean
    StPassCmprtMdCtrl_VCUAvl: invalidation-policy{data-element=StPassCmprtMdCtrl_VCUAvl/Val, handle-invalid=DONT-INVALIDATE}
      data Val: type=Boolean
    StPassCmprtMdRfCtrlSwCstStAvl: invalidation-policy{data-element=StPassCmprtMdRfCtrlSwCstStAvl/Val, handle-invalid=DONT-INVALIDATE}
      data Val: type=Boolean
    StSrvAvl: invalidation-policy{data-element=StSrvAvl/Val, handle-invalid=DONT-INVALIDATE}
      data Val: type=Boolean
    StSrvCfg: invalidation-policy{data-element=StSrvCfg/Val, handle-invalid=DONT-INVALIDATE}
      data Val: type=Boolean
    Validity: invalidation-policy{data-element=Validity/Val, handle-invalid=DONT-INVALIDATE}
      data Val: type=Boolean
    VehMovState: invalidation-policy{data-element=VehMovState/Val, handle-invalid=DONT-INVALIDATE}
      data Val: type=VehMovState1
    VehSpeed: invalidation-policy{data-element=VehSpeed/Val, handle-invalid=DONT-INVALIDATE}
      data Val: type=UInt16
    VoltSts: invalidation-policy{data-element=VoltSts/Val, handle-invalid=DONT-INVALIDATE}
      data Val: type=SeatSysVoltSt
package /PATAC/MSM/PortInterfaces
  parameter interface SeatEnable
    parameter data prototype Val: sw-calibration-access=READ-WRITE, type=Boolean
  7 x sender receiver interface:
    IfVeSMSbSecRwLtStBkReclnUpwdDnwdPosV: invalidation-policy{data-element=IfVeSMSbSecRwLtStBkReclnUpwdDnwdPosV/Val, handle-invalid=DONT-INVALIDATE}
      data Val: type=Boolean
    IfVeSMSbSecRwLtStFrwdBkwdPosV: invalidation-policy{data-element=IfVeSMSbSecRwLtStFrwdBkwdPosV/Val, handle-invalid=DONT-INVALIDATE}
      data Val: type=Boolean
    IfVeSMSbSecRwRtStBkReclnUpwdDnwdPosV: invalidation-policy{data-element=IfVeSMSbSecRwRtStBkReclnUpwdDnwdPosV/Val, handle-invalid=DONT-INVALIDATE}
      data Val: type=Boolean
    IfVeSMSbSecRwRtStFrwdBkwdPosV: invalidation-policy{data-element=IfVeSMSbSecRwRtStFrwdBkwdPosV/Val, handle-invalid=DONT-INVALIDATE}
      data Val: type=Boolean
    IfVeSMSuSecRwLtStBkReclnUpwdDnwdPos: invalidation-policy{data-element=IfVeSMSuSecRwLtStBkReclnUpwdDnwdPos/Val, handle-invalid=DONT-INVALIDATE}
      data Val: type=UInt16
    IfVeSMSuSecRwLtStFrwdBkwdPos: invalidation-policy{data-element=IfVeSMSuSecRwLtStFrwdBkwdPos/Val, handle-invalid=DONT-INVALIDATE}
      data Val: type=UInt16
    IfVeSMSuSecRwRtStBkReclnUpwdDnwdPos: invalidation-policy{data-element=IfVeSMSuSecRwRtStBkReclnUpwdDnwdPos/Val, handle-invalid=DONT-INVALIDATE}
      data Val: type=UInt16
package /PATAC/SignalLost
  sender receiver interface VeSignalLost_DataTpye: invalidation-policy{data-element=VeSignalLost_DataTpye/Val, handle-invalid=DONT-INVALIDATE}
    data Val: type=boolean
package /PortInterfaces
  sender receiver interface SeatSwActive: invalidation-policy{data-element=SeatSwActive/Val, handle-invalid=DONT-INVALIDATE}
    data Val: type=Boolean
